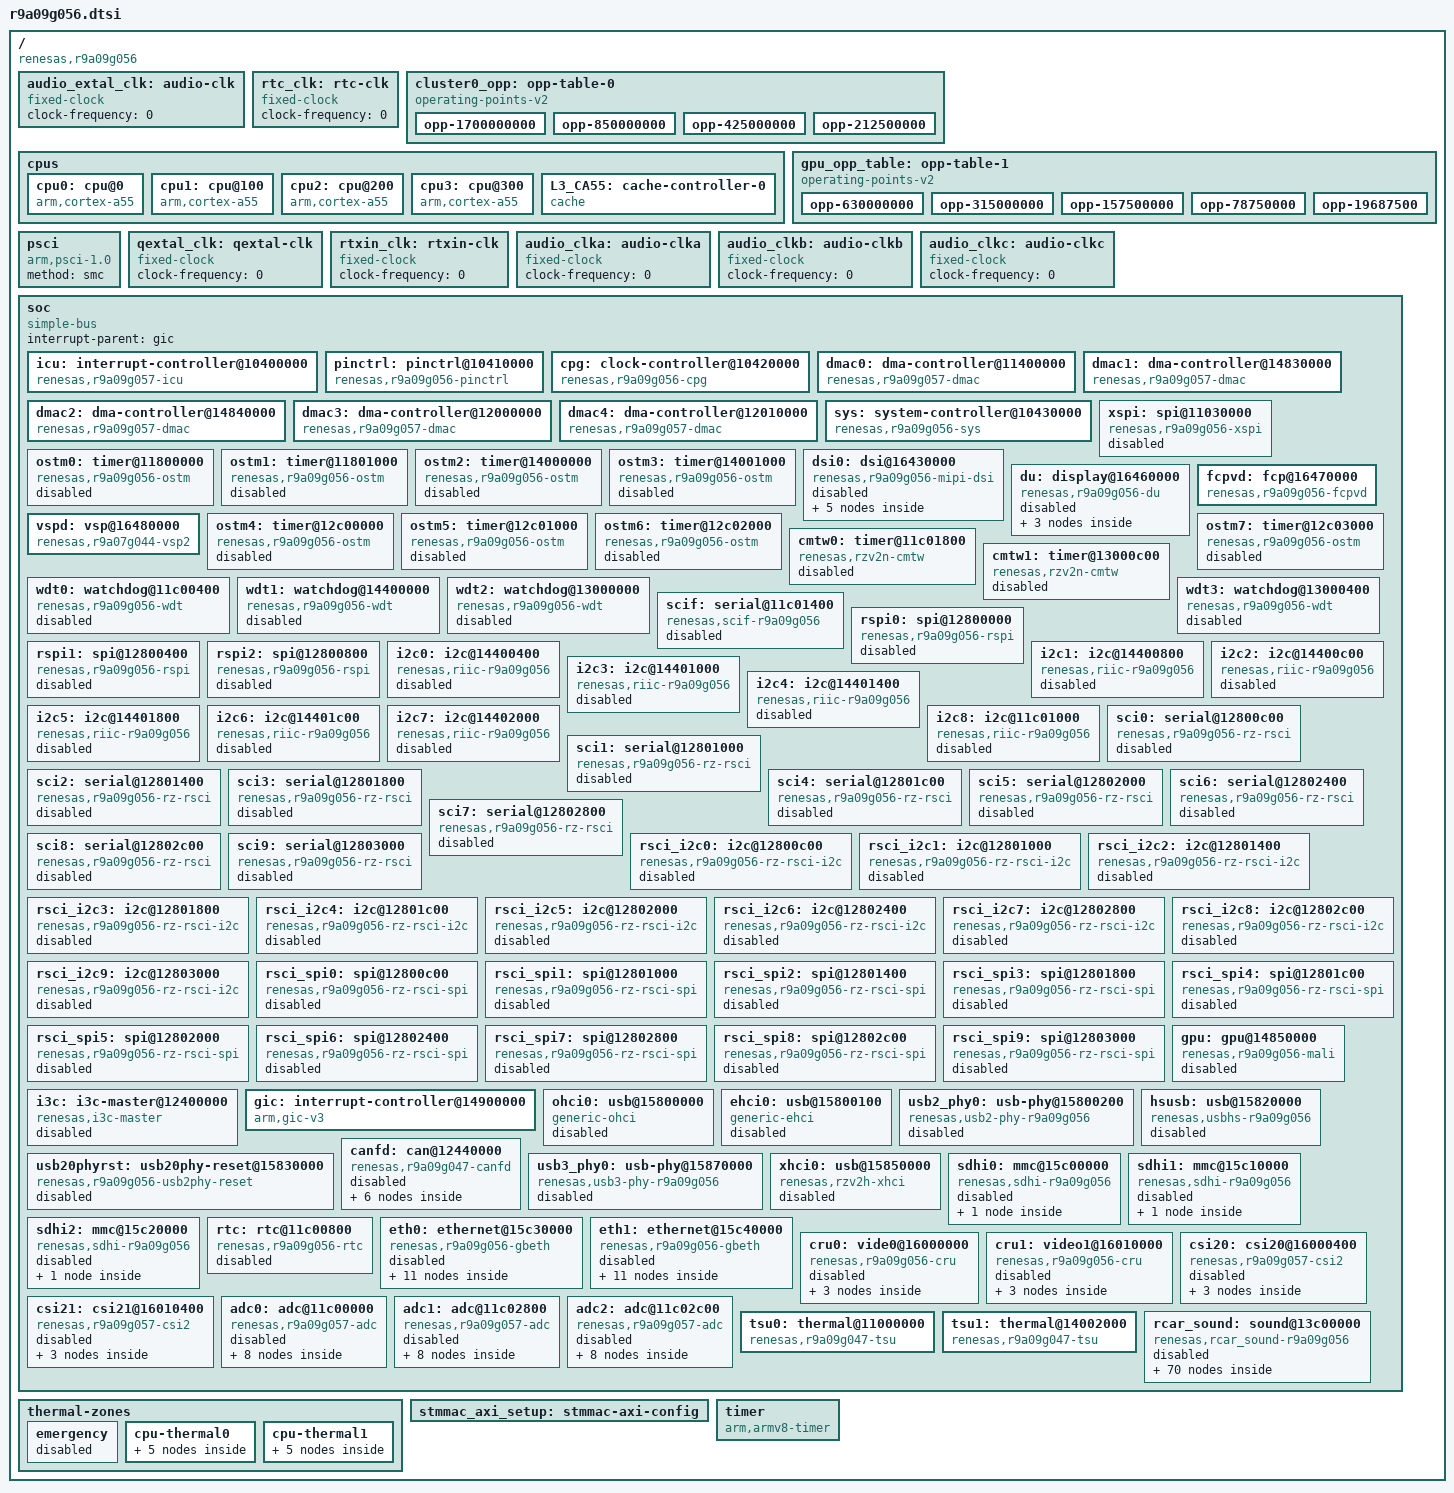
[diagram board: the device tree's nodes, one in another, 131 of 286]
// SPDX-License-Identifier: (GPL-2.0-only OR BSD-2-Clause)
/*
 * Device Tree Source for the RZ/V2N SoC
 *
 * Copyright (C) 2025 Renesas Electronics Corp.
 */

#include <dt-bindings/clock/renesas,r9a09g056-cpg.h>
#include <dt-bindings/interrupt-controller/arm-gic.h>
#include <dt-bindings/pinctrl/rzg2l-pinctrl.h>

/* RZV2N_Px = Offset address of PFC_P_mn  - 0x20 */
#define RZV2N_P0	0
#define RZV2N_P1	1
#define RZV2N_P2	2
#define RZV2N_P3	3
#define RZV2N_P4	4
#define RZV2N_P5	5
#define RZV2N_P6	6
#define RZV2N_P7	7
#define RZV2N_P8	8
#define RZV2N_P9	9
#define RZV2N_PA	10
#define RZV2N_PB	11

#define RZV2N_PORT_PINMUX(b, p, f)	RZG2L_PORT_PINMUX(RZV2N_P##b, p, f)
#define RZV2N_GPIO(port, pin)		RZG2L_GPIO(RZV2N_P##port, pin)

/ {
	compatible = "renesas,r9a09g056";
	#address-cells = <2>;
	#size-cells = <2>;

	audio_extal_clk: audio-clk {
		compatible = "fixed-clock";
		#clock-cells = <0>;
		/* This value must be overridden by the board */
		clock-frequency = <0>;
	};

	rtc_clk: rtc-clk {
		compatible = "fixed-clock";
		#clock-cells = <0>;
		/* This value must be overridden by the board */
		clock-frequency = <0>;
	};

	/*
	 * The default cluster table is based on the assumption that the PLLCA55 clock
	 * frequency is set to 1.7GHz. The PLLCA55 clock frequency can be set to
	 * 1.7/1.6/1.5/1.1 GHz based on the BOOTPLLCA_0/1 pins (and additionally can be
	 * clocked to 1.8GHz as well). The table below should be overridden in the board
	 * DTS based on the PLLCA55 clock frequency.
	 */
	cluster0_opp: opp-table-0 {
		compatible = "operating-points-v2";

		opp-1700000000 {
			opp-hz = /bits/ 64 <1700000000>;
			opp-microvolt = <900000>;
			clock-latency-ns = <300000>;
		};
		opp-850000000 {
			opp-hz = /bits/ 64 <850000000>;
			opp-microvolt = <800000>;
			clock-latency-ns = <300000>;
		};
		opp-425000000 {
			opp-hz = /bits/ 64 <425000000>;
			opp-microvolt = <800000>;
			clock-latency-ns = <300000>;
		};
		opp-212500000 {
			opp-hz = /bits/ 64 <212500000>;
			opp-microvolt = <800000>;
			clock-latency-ns = <300000>;
			opp-suspend;
		};
	};

	cpus {
		#address-cells = <1>;
		#size-cells = <0>;

		cpu0: cpu@0 {
			compatible = "arm,cortex-a55";
			reg = <0>;
			device_type = "cpu";
			next-level-cache = <&L3_CA55>;
			enable-method = "psci";
			clocks = <&cpg CPG_CORE R9A09G056_CA55_0_CORE_CLK0>;
			#cooling-cells = <2>;
			operating-points-v2 = <&cluster0_opp>;
		};

		cpu1: cpu@100 {
			compatible = "arm,cortex-a55";
			reg = <0x100>;
			device_type = "cpu";
			next-level-cache = <&L3_CA55>;
			enable-method = "psci";
			clocks = <&cpg CPG_CORE R9A09G056_CA55_0_CORE_CLK1>;
			#cooling-cells = <2>;
			operating-points-v2 = <&cluster0_opp>;
		};

		cpu2: cpu@200 {
			compatible = "arm,cortex-a55";
			reg = <0x200>;
			device_type = "cpu";
			next-level-cache = <&L3_CA55>;
			enable-method = "psci";
			clocks = <&cpg CPG_CORE R9A09G056_CA55_0_CORE_CLK2>;
			#cooling-cells = <2>;
			operating-points-v2 = <&cluster0_opp>;
		};

		cpu3: cpu@300 {
			compatible = "arm,cortex-a55";
			reg = <0x300>;
			device_type = "cpu";
			next-level-cache = <&L3_CA55>;
			enable-method = "psci";
			clocks = <&cpg CPG_CORE R9A09G056_CA55_0_CORE_CLK3>;
			#cooling-cells = <2>;
			operating-points-v2 = <&cluster0_opp>;
		};

		L3_CA55: cache-controller-0 {
			compatible = "cache";
			cache-unified;
			cache-size = <0x100000>;
			cache-level = <3>;
		};
	};

	gpu_opp_table: opp-table-1 {
		compatible = "operating-points-v2";

		opp-630000000 {
			opp-hz = /bits/ 64 <630000000>;
			opp-microvolt = <800000>;
		};

		opp-315000000 {
			opp-hz = /bits/ 64 <315000000>;
			opp-microvolt = <800000>;
		};

		opp-157500000 {
			opp-hz = /bits/ 64 <157500000>;
			opp-microvolt = <800000>;
		};

		opp-78750000 {
			opp-hz = /bits/ 64 <78750000>;
			opp-microvolt = <800000>;
		};

		opp-19687500 {
			opp-hz = /bits/ 64 <19687500>;
			opp-microvolt = <800000>;
		};
	};

	psci {
		compatible = "arm,psci-1.0", "arm,psci-0.2";
		method = "smc";
	};

	qextal_clk: qextal-clk {
		compatible = "fixed-clock";
		#clock-cells = <0>;
		/* This value must be overridden by the board */
		clock-frequency = <0>;
	};

	rtxin_clk: rtxin-clk {
		compatible = "fixed-clock";
		#clock-cells = <0>;
		/* This value must be overridden by the board */
		clock-frequency = <0>;
	};

	audio_clka: audio-clka {
		compatible = "fixed-clock";
		#clock-cells = <0>;
		/* This value must be overridden by the board */
		clock-frequency = <0>;
	};

	audio_clkb: audio-clkb {
		compatible = "fixed-clock";
		#clock-cells = <0>;
		/* This value must be overridden by the board */
		clock-frequency = <0>;
	};

	audio_clkc: audio-clkc {
		compatible = "fixed-clock";
		#clock-cells = <0>;
		/* This value must be overridden by the board */
		clock-frequency = <0>;
	};

	soc: soc {
		compatible = "simple-bus";
		interrupt-parent = <&gic>;
		#address-cells = <2>;
		#size-cells = <2>;
		ranges;

		icu: interrupt-controller@10400000 {
			compatible = "renesas,r9a09g057-icu";
			reg = <0 0x10400000 0 0x10000>;
			#interrupt-cells = <2>;
			#address-cells = <0>;
			interrupt-controller;
			interrupts = <GIC_SPI 0 IRQ_TYPE_LEVEL_HIGH>,
				     <GIC_SPI 1 IRQ_TYPE_LEVEL_HIGH>,
				     <GIC_SPI 2 IRQ_TYPE_LEVEL_HIGH>,
				     <GIC_SPI 3 IRQ_TYPE_LEVEL_HIGH>,
				     <GIC_SPI 4 IRQ_TYPE_LEVEL_HIGH>,
				     <GIC_SPI 5 IRQ_TYPE_LEVEL_HIGH>,
				     <GIC_SPI 6 IRQ_TYPE_LEVEL_HIGH>,
				     <GIC_SPI 7 IRQ_TYPE_LEVEL_HIGH>,
				     <GIC_SPI 8 IRQ_TYPE_LEVEL_HIGH>,
				     <GIC_SPI 9 IRQ_TYPE_LEVEL_HIGH>,
				     <GIC_SPI 10 IRQ_TYPE_LEVEL_HIGH>,
				     <GIC_SPI 11 IRQ_TYPE_LEVEL_HIGH>,
				     <GIC_SPI 12 IRQ_TYPE_LEVEL_HIGH>,
				     <GIC_SPI 13 IRQ_TYPE_LEVEL_HIGH>,
				     <GIC_SPI 14 IRQ_TYPE_LEVEL_HIGH>,
				     <GIC_SPI 15 IRQ_TYPE_LEVEL_HIGH>,
				     <GIC_SPI 16 IRQ_TYPE_LEVEL_HIGH>,
				     <GIC_SPI 419 IRQ_TYPE_LEVEL_HIGH>,
				     <GIC_SPI 420 IRQ_TYPE_LEVEL_HIGH>,
				     <GIC_SPI 421 IRQ_TYPE_LEVEL_HIGH>,
				     <GIC_SPI 422 IRQ_TYPE_LEVEL_HIGH>,
				     <GIC_SPI 423 IRQ_TYPE_LEVEL_HIGH>,
				     <GIC_SPI 424 IRQ_TYPE_LEVEL_HIGH>,
				     <GIC_SPI 425 IRQ_TYPE_LEVEL_HIGH>,
				     <GIC_SPI 426 IRQ_TYPE_LEVEL_HIGH>,
				     <GIC_SPI 427 IRQ_TYPE_LEVEL_HIGH>,
				     <GIC_SPI 428 IRQ_TYPE_LEVEL_HIGH>,
				     <GIC_SPI 429 IRQ_TYPE_LEVEL_HIGH>,
				     <GIC_SPI 430 IRQ_TYPE_LEVEL_HIGH>,
				     <GIC_SPI 431 IRQ_TYPE_LEVEL_HIGH>,
				     <GIC_SPI 432 IRQ_TYPE_LEVEL_HIGH>,
				     <GIC_SPI 433 IRQ_TYPE_LEVEL_HIGH>,
				     <GIC_SPI 434 IRQ_TYPE_LEVEL_HIGH>,
				     <GIC_SPI 435 IRQ_TYPE_LEVEL_HIGH>,
				     <GIC_SPI 436 IRQ_TYPE_LEVEL_HIGH>,
				     <GIC_SPI 437 IRQ_TYPE_LEVEL_HIGH>,
				     <GIC_SPI 438 IRQ_TYPE_LEVEL_HIGH>,
				     <GIC_SPI 439 IRQ_TYPE_LEVEL_HIGH>,
				     <GIC_SPI 440 IRQ_TYPE_LEVEL_HIGH>,
				     <GIC_SPI 441 IRQ_TYPE_LEVEL_HIGH>,
				     <GIC_SPI 442 IRQ_TYPE_LEVEL_HIGH>,
				     <GIC_SPI 443 IRQ_TYPE_LEVEL_HIGH>,
				     <GIC_SPI 444 IRQ_TYPE_LEVEL_HIGH>,
				     <GIC_SPI 445 IRQ_TYPE_LEVEL_HIGH>,
				     <GIC_SPI 446 IRQ_TYPE_LEVEL_HIGH>,
				     <GIC_SPI 447 IRQ_TYPE_LEVEL_HIGH>,
				     <GIC_SPI 448 IRQ_TYPE_LEVEL_HIGH>,
				     <GIC_SPI 449 IRQ_TYPE_LEVEL_HIGH>,
				     <GIC_SPI 450 IRQ_TYPE_LEVEL_HIGH>,
				     <GIC_SPI 262 IRQ_TYPE_EDGE_RISING>,
				     <GIC_SPI 263 IRQ_TYPE_EDGE_RISING>,
				     <GIC_SPI 264 IRQ_TYPE_EDGE_RISING>,
				     <GIC_SPI 265 IRQ_TYPE_EDGE_RISING>,
				     <GIC_SPI 266 IRQ_TYPE_LEVEL_HIGH>,
				     <GIC_SPI 451 IRQ_TYPE_LEVEL_HIGH>,
				     <GIC_SPI 452 IRQ_TYPE_LEVEL_HIGH>,
				     <GIC_SPI 453 IRQ_TYPE_LEVEL_HIGH>,
				     <GIC_SPI 454 IRQ_TYPE_LEVEL_HIGH>;
			interrupt-names = "nmi",
					  "port_irq0", "port_irq1", "port_irq2",
					  "port_irq3", "port_irq4", "port_irq5",
					  "port_irq6", "port_irq7", "port_irq8",
					  "port_irq9", "port_irq10", "port_irq11",
					  "port_irq12", "port_irq13", "port_irq14",
					  "port_irq15",
					  "tint0", "tint1", "tint2", "tint3",
					  "tint4", "tint5", "tint6", "tint7",
					  "tint8", "tint9", "tint10", "tint11",
					  "tint12", "tint13", "tint14", "tint15",
					  "tint16", "tint17", "tint18", "tint19",
					  "tint20", "tint21", "tint22", "tint23",
					  "tint24", "tint25", "tint26", "tint27",
					  "tint28", "tint29", "tint30", "tint31",
					  "int-ca55-0", "int-ca55-1",
					  "int-ca55-2", "int-ca55-3",
					  "icu-error-ca55",
					  "gpt-u0-gtciada", "gpt-u0-gtciadb",
					  "gpt-u1-gtciada", "gpt-u1-gtciadb";
			clocks = <&cpg CPG_MOD 0x5>;
			clock-names = "pclk";
			power-domains = <&cpg>;
			resets = <&cpg 0x36>;
		};

		pinctrl: pinctrl@10410000 {
			compatible = "renesas,r9a09g056-pinctrl";
			reg = <0 0x10410000 0 0x10000>;
			clocks = <&cpg CPG_CORE R9A09G056_IOTOP_0_SHCLK>;
			gpio-controller;
			#gpio-cells = <2>;
			gpio-ranges = <&pinctrl 0 0 96>;
			interrupt-parent = <&icu>;
			power-domains = <&cpg>;
			resets = <&cpg 0xa5>, <&cpg 0xa6>;
		};

		cpg: clock-controller@10420000 {
			compatible = "renesas,r9a09g056-cpg";
			reg = <0 0x10420000 0 0x10000>;
			clocks = <&audio_extal_clk>, <&audio_clka>,
				 <&audio_clkb>, <&audio_clkc>,
				 <&rtxin_clk>, <&qextal_clk>;
			clock-names = "audio_extal", "audio_clka",
				      "audio_clkb", "audio_clkc",
				      "rtxin", "qextal";
			#clock-cells = <2>;
			#reset-cells = <1>;
			#power-domain-cells = <0>;
		};

		dmac0: dma-controller@11400000 {
			compatible = "renesas,r9a09g057-dmac";
			reg = <0 0x11400000 0 0x10000>;
			interrupts = <GIC_SPI 499 IRQ_TYPE_EDGE_RISING>,
				     <GIC_SPI 89 IRQ_TYPE_EDGE_RISING>,
				     <GIC_SPI 90 IRQ_TYPE_EDGE_RISING>,
				     <GIC_SPI 91 IRQ_TYPE_EDGE_RISING>,
				     <GIC_SPI 92 IRQ_TYPE_EDGE_RISING>,
				     <GIC_SPI 93 IRQ_TYPE_EDGE_RISING>,
				     <GIC_SPI 94 IRQ_TYPE_EDGE_RISING>,
				     <GIC_SPI 95 IRQ_TYPE_EDGE_RISING>,
				     <GIC_SPI 96 IRQ_TYPE_EDGE_RISING>,
				     <GIC_SPI 97 IRQ_TYPE_EDGE_RISING>,
				     <GIC_SPI 98 IRQ_TYPE_EDGE_RISING>,
				     <GIC_SPI 99 IRQ_TYPE_EDGE_RISING>,
				     <GIC_SPI 100 IRQ_TYPE_EDGE_RISING>,
				     <GIC_SPI 101 IRQ_TYPE_EDGE_RISING>,
				     <GIC_SPI 102 IRQ_TYPE_EDGE_RISING>,
				     <GIC_SPI 103 IRQ_TYPE_EDGE_RISING>,
				     <GIC_SPI 104 IRQ_TYPE_EDGE_RISING>;
			interrupt-names = "error",
					  "ch0", "ch1", "ch2", "ch3",
					  "ch4", "ch5", "ch6", "ch7",
					  "ch8", "ch9", "ch10", "ch11",
					  "ch12", "ch13", "ch14", "ch15";
			clocks = <&cpg CPG_MOD 0x0>;
			power-domains = <&cpg>;
			resets = <&cpg 0x31>;
			#dma-cells = <1>;
			dma-channels = <16>;
			renesas,icu = <&icu 4>;
		};

		dmac1: dma-controller@14830000 {
			compatible = "renesas,r9a09g057-dmac";
			reg = <0 0x14830000 0 0x10000>;
			interrupts = <GIC_SPI 495 IRQ_TYPE_EDGE_RISING>,
				     <GIC_SPI 25 IRQ_TYPE_EDGE_RISING>,
				     <GIC_SPI 26 IRQ_TYPE_EDGE_RISING>,
				     <GIC_SPI 27 IRQ_TYPE_EDGE_RISING>,
				     <GIC_SPI 28 IRQ_TYPE_EDGE_RISING>,
				     <GIC_SPI 29 IRQ_TYPE_EDGE_RISING>,
				     <GIC_SPI 30 IRQ_TYPE_EDGE_RISING>,
				     <GIC_SPI 31 IRQ_TYPE_EDGE_RISING>,
				     <GIC_SPI 32 IRQ_TYPE_EDGE_RISING>,
				     <GIC_SPI 33 IRQ_TYPE_EDGE_RISING>,
				     <GIC_SPI 34 IRQ_TYPE_EDGE_RISING>,
				     <GIC_SPI 35 IRQ_TYPE_EDGE_RISING>,
				     <GIC_SPI 36 IRQ_TYPE_EDGE_RISING>,
				     <GIC_SPI 37 IRQ_TYPE_EDGE_RISING>,
				     <GIC_SPI 38 IRQ_TYPE_EDGE_RISING>,
				     <GIC_SPI 39 IRQ_TYPE_EDGE_RISING>,
				     <GIC_SPI 40 IRQ_TYPE_EDGE_RISING>;
			interrupt-names = "error",
					  "ch0", "ch1", "ch2", "ch3",
					  "ch4", "ch5", "ch6", "ch7",
					  "ch8", "ch9", "ch10", "ch11",
					  "ch12", "ch13", "ch14", "ch15";
			clocks = <&cpg CPG_MOD 0x1>;
			power-domains = <&cpg>;
			resets = <&cpg 0x32>;
			#dma-cells = <1>;
			dma-channels = <16>;
			renesas,icu = <&icu 0>;
		};

		dmac2: dma-controller@14840000 {
			compatible = "renesas,r9a09g057-dmac";
			reg = <0 0x14840000 0 0x10000>;
			interrupts = <GIC_SPI 496 IRQ_TYPE_EDGE_RISING>,
				     <GIC_SPI 41 IRQ_TYPE_EDGE_RISING>,
				     <GIC_SPI 42 IRQ_TYPE_EDGE_RISING>,
				     <GIC_SPI 43 IRQ_TYPE_EDGE_RISING>,
				     <GIC_SPI 44 IRQ_TYPE_EDGE_RISING>,
				     <GIC_SPI 45 IRQ_TYPE_EDGE_RISING>,
				     <GIC_SPI 46 IRQ_TYPE_EDGE_RISING>,
				     <GIC_SPI 47 IRQ_TYPE_EDGE_RISING>,
				     <GIC_SPI 48 IRQ_TYPE_EDGE_RISING>,
				     <GIC_SPI 49 IRQ_TYPE_EDGE_RISING>,
				     <GIC_SPI 50 IRQ_TYPE_EDGE_RISING>,
				     <GIC_SPI 51 IRQ_TYPE_EDGE_RISING>,
				     <GIC_SPI 52 IRQ_TYPE_EDGE_RISING>,
				     <GIC_SPI 53 IRQ_TYPE_EDGE_RISING>,
				     <GIC_SPI 54 IRQ_TYPE_EDGE_RISING>,
				     <GIC_SPI 55 IRQ_TYPE_EDGE_RISING>,
				     <GIC_SPI 56 IRQ_TYPE_EDGE_RISING>;
			interrupt-names = "error",
					  "ch0", "ch1", "ch2", "ch3",
					  "ch4", "ch5", "ch6", "ch7",
					  "ch8", "ch9", "ch10", "ch11",
					  "ch12", "ch13", "ch14", "ch15";
			clocks = <&cpg CPG_MOD 0x2>;
			power-domains = <&cpg>;
			resets = <&cpg 0x33>;
			#dma-cells = <1>;
			dma-channels = <16>;
			renesas,icu = <&icu 1>;
		};

		dmac3: dma-controller@12000000 {
			compatible = "renesas,r9a09g057-dmac";
			reg = <0 0x12000000 0 0x10000>;
			interrupts = <GIC_SPI 497 IRQ_TYPE_EDGE_RISING>,
				     <GIC_SPI 57 IRQ_TYPE_EDGE_RISING>,
				     <GIC_SPI 58 IRQ_TYPE_EDGE_RISING>,
				     <GIC_SPI 59 IRQ_TYPE_EDGE_RISING>,
				     <GIC_SPI 60 IRQ_TYPE_EDGE_RISING>,
				     <GIC_SPI 61 IRQ_TYPE_EDGE_RISING>,
				     <GIC_SPI 62 IRQ_TYPE_EDGE_RISING>,
				     <GIC_SPI 63 IRQ_TYPE_EDGE_RISING>,
				     <GIC_SPI 64 IRQ_TYPE_EDGE_RISING>,
				     <GIC_SPI 65 IRQ_TYPE_EDGE_RISING>,
				     <GIC_SPI 66 IRQ_TYPE_EDGE_RISING>,
				     <GIC_SPI 67 IRQ_TYPE_EDGE_RISING>,
				     <GIC_SPI 68 IRQ_TYPE_EDGE_RISING>,
				     <GIC_SPI 69 IRQ_TYPE_EDGE_RISING>,
				     <GIC_SPI 70 IRQ_TYPE_EDGE_RISING>,
				     <GIC_SPI 71 IRQ_TYPE_EDGE_RISING>,
				     <GIC_SPI 72 IRQ_TYPE_EDGE_RISING>;
			interrupt-names = "error",
					  "ch0", "ch1", "ch2", "ch3",
					  "ch4", "ch5", "ch6", "ch7",
					  "ch8", "ch9", "ch10", "ch11",
					  "ch12", "ch13", "ch14", "ch15";
			clocks = <&cpg CPG_MOD 0x3>;
			power-domains = <&cpg>;
			resets = <&cpg 0x34>;
			#dma-cells = <1>;
			dma-channels = <16>;
			renesas,icu = <&icu 2>;
		};

		dmac4: dma-controller@12010000 {
			compatible = "renesas,r9a09g057-dmac";
			reg = <0 0x12010000 0 0x10000>;
			interrupts = <GIC_SPI 498 IRQ_TYPE_EDGE_RISING>,
				     <GIC_SPI 73 IRQ_TYPE_EDGE_RISING>,
				     <GIC_SPI 74 IRQ_TYPE_EDGE_RISING>,
				     <GIC_SPI 75 IRQ_TYPE_EDGE_RISING>,
				     <GIC_SPI 76 IRQ_TYPE_EDGE_RISING>,
				     <GIC_SPI 77 IRQ_TYPE_EDGE_RISING>,
				     <GIC_SPI 78 IRQ_TYPE_EDGE_RISING>,
				     <GIC_SPI 79 IRQ_TYPE_EDGE_RISING>,
				     <GIC_SPI 80 IRQ_TYPE_EDGE_RISING>,
				     <GIC_SPI 81 IRQ_TYPE_EDGE_RISING>,
				     <GIC_SPI 82 IRQ_TYPE_EDGE_RISING>,
				     <GIC_SPI 83 IRQ_TYPE_EDGE_RISING>,
				     <GIC_SPI 84 IRQ_TYPE_EDGE_RISING>,
				     <GIC_SPI 85 IRQ_TYPE_EDGE_RISING>,
				     <GIC_SPI 86 IRQ_TYPE_EDGE_RISING>,
				     <GIC_SPI 87 IRQ_TYPE_EDGE_RISING>,
				     <GIC_SPI 88 IRQ_TYPE_EDGE_RISING>;
			interrupt-names = "error",
					  "ch0", "ch1", "ch2", "ch3",
					  "ch4", "ch5", "ch6", "ch7",
					  "ch8", "ch9", "ch10", "ch11",
					  "ch12", "ch13", "ch14", "ch15";
			clocks = <&cpg CPG_MOD 0x4>;
			power-domains = <&cpg>;
			resets = <&cpg 0x35>;
			#dma-cells = <1>;
			dma-channels = <16>;
			renesas,icu = <&icu 3>;
		};

		sys: system-controller@10430000 {
			compatible = "renesas,r9a09g056-sys", "syscon";
			reg = <0 0x10430000 0 0x10000>;
			clocks = <&cpg CPG_CORE R9A09G056_SYS_0_PCLK>;
			resets = <&cpg 0x30>;
		};

		xspi: spi@11030000 {
			compatible = "renesas,r9a09g056-xspi", "renesas,r9a09g047-xspi";
			reg = <0 0x11030000 0 0x10000>,
			      <0 0x20000000 0 0x10000000>;
			reg-names = "regs", "dirmap";
			interrupts = <GIC_SPI 228 IRQ_TYPE_EDGE_RISING>,
				     <GIC_SPI 229 IRQ_TYPE_EDGE_RISING>;
			interrupt-names = "pulse", "err_pulse";
			clocks = <&cpg CPG_MOD 0x9f>,
				 <&cpg CPG_MOD 0xa0>,
				 <&cpg CPG_CORE R9A09G056_SPI_CLK_SPI>,
				 <&cpg CPG_MOD 0xa1>;
			clock-names = "ahb", "axi", "spi", "spix2";
			resets = <&cpg 0xa3>, <&cpg 0xa4>;
			reset-names = "hresetn", "aresetn";
			power-domains = <&cpg>;
			#address-cells = <1>;
			#size-cells = <0>;
			status = "disabled";
		};

		ostm0: timer@11800000 {
			compatible = "renesas,r9a09g056-ostm", "renesas,ostm";
			reg = <0x0 0x11800000 0x0 0x1000>;
			interrupts = <GIC_SPI 17 IRQ_TYPE_EDGE_RISING>;
			clocks = <&cpg CPG_MOD 0x43>;
			resets = <&cpg 0x6d>;
			power-domains = <&cpg>;
			status = "disabled";
		};

		ostm1: timer@11801000 {
			compatible = "renesas,r9a09g056-ostm", "renesas,ostm";
			reg = <0x0 0x11801000 0x0 0x1000>;
			interrupts = <GIC_SPI 18 IRQ_TYPE_EDGE_RISING>;
			clocks = <&cpg CPG_MOD 0x44>;
			resets = <&cpg 0x6e>;
			power-domains = <&cpg>;
			status = "disabled";
		};

		ostm2: timer@14000000 {
			compatible = "renesas,r9a09g056-ostm", "renesas,ostm";
			reg = <0x0 0x14000000 0x0 0x1000>;
			interrupts = <GIC_SPI 19 IRQ_TYPE_EDGE_RISING>;
			clocks = <&cpg CPG_MOD 0x45>;
			resets = <&cpg 0x6f>;
			power-domains = <&cpg>;
			status = "disabled";
		};

		ostm3: timer@14001000 {
			compatible = "renesas,r9a09g056-ostm", "renesas,ostm";
			reg = <0x0 0x14001000 0x0 0x1000>;
			interrupts = <GIC_SPI 20 IRQ_TYPE_EDGE_RISING>;
			clocks = <&cpg CPG_MOD 0x46>;
			resets = <&cpg 0x70>;
			power-domains = <&cpg>;
			status = "disabled";
		};

		dsi0: dsi@16430000 {
			compatible = "renesas,r9a09g056-mipi-dsi",
				     "renesas,rzv2n-mipi-dsi";
			reg = <0 0x16430000 0 0x20000>;
			clocks = <&cpg CPG_MOD 0xe8>,
				 <&cpg CPG_MOD 0xe9>,
				 <&cpg CPG_MOD 0xea>,
				 <&cpg CPG_MOD 0xeb>,
				 <&cpg CPG_MOD 0xec>;
			clock-names = "pclk", "aclk",
				      "vclk0", "lpclk", "pllclk";
			resets = <&cpg 0xd7>,
				 <&cpg 0xd8>;
			reset-names = "prst", "arst";
			power-domains = <&cpg>;
			status = "disabled";

			ports {
				#address-cells = <1>;
				#size-cells = <0>;

				port@0 {
					reg = <0>;
					dsi0_in: endpoint {
						remote-endpoint = <&du_out_dsi0>;
					};
				};

				port@1 {
					reg = <1>;
					dsi0_out: endpoint {
					};
				};
			};
		};

		du: display@16460000 {
			compatible = "renesas,r9a09g056-du";
			reg = <0 0x16460000 0 0x10000>;
			interrupts = <GIC_SPI 882 IRQ_TYPE_LEVEL_HIGH>;
			clocks = <&cpg CPG_MOD 0xed>,
				 <&cpg CPG_MOD 0xee>,
				 <&cpg CPG_MOD 0xef>;
			clock-names = "aclk0", "pclk0", "vclk0";
			power-domains = <&cpg>;
			resets = <&cpg 0xdc>;
			renesas,vsps = <&vspd 0>;
			status = "disabled";

			ports {
				#address-cells = <1>;
				#size-cells = <0>;

				port@0 {
					reg = <0>;
					du_out_dsi0: endpoint {
						remote-endpoint = <&dsi0_in>;
					};
				};
			};
		};

		fcpvd: fcp@16470000 {
			compatible = "renesas,r9a09g056-fcpvd",
				     "renesas,fcpv";
			reg = <0 0x10880000 0 0x10000>;
			clocks = <&cpg CPG_MOD 0xed>,
				 <&cpg CPG_MOD 0xee>,
				 <&cpg CPG_MOD 0xef>;
			clock-names = "aclk", "pclk", "vclk";
			resets = <&cpg 0xdc>;
			power-domains = <&cpg>;
		};

		vspd: vsp@16480000 {
			compatible = "renesas,r9a07g044-vsp2";
			reg = <0 0x16480000 0 0x10000>;
			interrupts = <GIC_SPI 881 IRQ_TYPE_LEVEL_HIGH>;
			clocks = <&cpg CPG_MOD 0xed>,
				 <&cpg CPG_MOD 0xee>,
				 <&cpg CPG_MOD 0xef>;
			clock-names = "aclk", "pclk", "vclk";
			resets = <&cpg 0xdc>;
			power-domains = <&cpg>;
			renesas,fcp = <&fcpvd>;
		};

		ostm4: timer@12c00000 {
			compatible = "renesas,r9a09g056-ostm", "renesas,ostm";
			reg = <0x0 0x12c00000 0x0 0x1000>;
			interrupts = <GIC_SPI 21 IRQ_TYPE_EDGE_RISING>;
			clocks = <&cpg CPG_MOD 0x47>;
			resets = <&cpg 0x71>;
			power-domains = <&cpg>;
			status = "disabled";
		};

		ostm5: timer@12c01000 {
			compatible = "renesas,r9a09g056-ostm", "renesas,ostm";
			reg = <0x0 0x12c01000 0x0 0x1000>;
			interrupts = <GIC_SPI 22 IRQ_TYPE_EDGE_RISING>;
			clocks = <&cpg CPG_MOD 0x48>;
			resets = <&cpg 0x72>;
			power-domains = <&cpg>;
			status = "disabled";
		};

		ostm6: timer@12c02000 {
			compatible = "renesas,r9a09g056-ostm", "renesas,ostm";
			reg = <0x0 0x12c02000 0x0 0x1000>;
			interrupts = <GIC_SPI 23 IRQ_TYPE_EDGE_RISING>;
			clocks = <&cpg CPG_MOD 0x49>;
			resets = <&cpg 0x73>;
			power-domains = <&cpg>;
			status = "disabled";
		};

		ostm7: timer@12c03000 {
			compatible = "renesas,r9a09g056-ostm", "renesas,ostm";
			reg = <0x0 0x12c03000 0x0 0x1000>;
			interrupts = <GIC_SPI 24 IRQ_TYPE_EDGE_RISING>;
			clocks = <&cpg CPG_MOD 0x4a>;
			resets = <&cpg 0x74>;
			power-domains = <&cpg>;
			status = "disabled";
		};

		cmtw0: timer@11c01800 {
			compatible = "renesas,rzv2n-cmtw";
			reg = <0 0x11c01800 0 0x1000>;
			interrupts = <GIC_SPI 455 IRQ_TYPE_EDGE_RISING>,
				     <GIC_SPI 456 IRQ_TYPE_EDGE_RISING>,
				     <GIC_SPI 457 IRQ_TYPE_EDGE_RISING>,
				     <GIC_SPI 458 IRQ_TYPE_EDGE_RISING>;
			clocks = <&cpg CPG_MOD 0x3b>, <&cpg CPG_MOD 0x3c>,
				 <&cpg CPG_MOD 0x3d>, <&cpg CPG_MOD 0x3e>;
			clock-names = "fck0", "fck1", "fck2", "fck3";
			resets = <&cpg 0x65>, <&cpg 0x66>,
				 <&cpg 0x67>, <&cpg 0x68>;
			power-domains = <&cpg>;
			status = "disabled";
		};

		cmtw1: timer@13000c00 {
			compatible = "renesas,rzv2n-cmtw";
			reg = <0 0x13000c00 0 0x1000>;
			interrupts = <GIC_SPI 459 IRQ_TYPE_EDGE_RISING>,
				     <GIC_SPI 460 IRQ_TYPE_EDGE_RISING>,
				     <GIC_SPI 461 IRQ_TYPE_EDGE_RISING>,
				     <GIC_SPI 462 IRQ_TYPE_EDGE_RISING>;
			clocks = <&cpg CPG_MOD 0x3f>, <&cpg CPG_MOD 0x40>,
				 <&cpg CPG_MOD 0x41>, <&cpg CPG_MOD 0x42>;
			clock-names = "fck0", "fck1", "fck2", "fck3";
			resets = <&cpg 0x69>, <&cpg 0x6a>,
				 <&cpg 0x6b>, <&cpg 0x6c>;
			power-domains = <&cpg>;
			status = "disabled";
		};

		wdt0: watchdog@11c00400 {
			compatible = "renesas,r9a09g056-wdt", "renesas,r9a09g057-wdt";
			reg = <0 0x11c00400 0 0x400>;
			clocks = <&cpg CPG_MOD 0x4b>, <&cpg CPG_MOD 0x4c>;
			clock-names = "pclk", "oscclk";
			resets = <&cpg 0x75>;
			power-domains = <&cpg>;
			status = "disabled";
		};

		wdt1: watchdog@14400000 {
			compatible = "renesas,r9a09g056-wdt", "renesas,r9a09g057-wdt";
			reg = <0 0x14400000 0 0x400>;
			clocks = <&cpg CPG_MOD 0x4d>, <&cpg CPG_MOD 0x4e>;
			clock-names = "pclk", "oscclk";
			resets = <&cpg 0x76>;
			power-domains = <&cpg>;
			status = "disabled";
		};

		wdt2: watchdog@13000000 {
			compatible = "renesas,r9a09g056-wdt", "renesas,r9a09g057-wdt";
			reg = <0 0x13000000 0 0x400>;
			clocks = <&cpg CPG_MOD 0x4f>, <&cpg CPG_MOD 0x50>;
			clock-names = "pclk", "oscclk";
			resets = <&cpg 0x77>;
			power-domains = <&cpg>;
			status = "disabled";
		};

		wdt3: watchdog@13000400 {
			compatible = "renesas,r9a09g056-wdt", "renesas,r9a09g057-wdt";
			reg = <0 0x13000400 0 0x400>;
			clocks = <&cpg CPG_MOD 0x51>, <&cpg CPG_MOD 0x52>;
			clock-names = "pclk", "oscclk";
			resets = <&cpg 0x78>;
			power-domains = <&cpg>;
			status = "disabled";
		};

		scif: serial@11c01400 {
			compatible = "renesas,scif-r9a09g056",
				     "renesas,scif-r9a09g057";
			reg = <0 0x11c01400 0 0x400>;
			interrupts = <GIC_SPI 529 IRQ_TYPE_LEVEL_HIGH>,
				     <GIC_SPI 532 IRQ_TYPE_LEVEL_HIGH>,
				     <GIC_SPI 533 IRQ_TYPE_LEVEL_HIGH>,
				     <GIC_SPI 530 IRQ_TYPE_LEVEL_HIGH>,
				     <GIC_SPI 534 IRQ_TYPE_LEVEL_HIGH>,
				     <GIC_SPI 531 IRQ_TYPE_LEVEL_HIGH>,
				     <GIC_SPI 535 IRQ_TYPE_LEVEL_HIGH>,
				     <GIC_SPI 536 IRQ_TYPE_EDGE_RISING>,
				     <GIC_SPI 537 IRQ_TYPE_EDGE_RISING>;
			interrupt-names = "eri", "rxi", "txi", "bri", "dri",
					  "tei", "tei-dri", "rxi-edge", "txi-edge";
			clocks = <&cpg CPG_MOD 0x8f>;
			clock-names = "fck";
			power-domains = <&cpg>;
			resets = <&cpg 0x95>;
			status = "disabled";
		};

		rspi0: spi@12800000 {
			compatible = "renesas,r9a09g056-rspi",
				     "renesas,r9a09g057-rspi";
			reg = <0x0 0x12800000 0x0 0x400>;
			interrupts = <GIC_SPI 105 IRQ_TYPE_LEVEL_HIGH>,
				     <GIC_SPI 106 IRQ_TYPE_LEVEL_HIGH>,
				     <GIC_SPI 107 IRQ_TYPE_EDGE_RISING>,
				     <GIC_SPI 500 IRQ_TYPE_EDGE_RISING>,
				     <GIC_SPI 501 IRQ_TYPE_EDGE_RISING>;
			interrupt-names = "idle", "error", "end", "rx", "tx";
			clocks = <&cpg CPG_MOD 0x54>,
				 <&cpg CPG_MOD 0x55>,
				 <&cpg CPG_MOD 0x56>;
			clock-names = "pclk", "pclk_sfr", "tclk";
			resets = <&cpg 0x7b>, <&cpg 0x7c>;
			reset-names = "presetn", "tresetn";
			power-domains = <&cpg>;
			#address-cells = <1>;
			#size-cells = <0>;
			status = "disabled";
		};

		rspi1: spi@12800400 {
			compatible = "renesas,r9a09g056-rspi",
				     "renesas,r9a09g057-rspi";
			reg = <0x0 0x12800400 0x0 0x400>;
			interrupts = <GIC_SPI 108 IRQ_TYPE_LEVEL_HIGH>,
				     <GIC_SPI 109 IRQ_TYPE_LEVEL_HIGH>,
				     <GIC_SPI 110 IRQ_TYPE_EDGE_RISING>,
				     <GIC_SPI 502 IRQ_TYPE_EDGE_RISING>,
				     <GIC_SPI 503 IRQ_TYPE_EDGE_RISING>;
			interrupt-names = "idle", "error", "end", "rx", "tx";
			clocks = <&cpg CPG_MOD 0x57>,
				 <&cpg CPG_MOD 0x58>,
				 <&cpg CPG_MOD 0x59>;
			clock-names = "pclk", "pclk_sfr", "tclk";
			resets = <&cpg 0x7d>, <&cpg 0x7e>;
			reset-names = "presetn", "tresetn";
			power-domains = <&cpg>;
			#address-cells = <1>;
			#size-cells = <0>;
			status = "disabled";
		};

		rspi2: spi@12800800 {
			compatible = "renesas,r9a09g056-rspi",
				     "renesas,r9a09g057-rspi";
			reg = <0x0 0x12800800 0x0 0x400>;
			interrupts = <GIC_SPI 111 IRQ_TYPE_LEVEL_HIGH>,
				     <GIC_SPI 112 IRQ_TYPE_LEVEL_HIGH>,
				     <GIC_SPI 113 IRQ_TYPE_EDGE_RISING>,
				     <GIC_SPI 504 IRQ_TYPE_EDGE_RISING>,
				     <GIC_SPI 505 IRQ_TYPE_EDGE_RISING>;
			interrupt-names = "idle", "error", "end", "rx", "tx";
			clocks = <&cpg CPG_MOD 0x5a>,
				 <&cpg CPG_MOD 0x5b>,
				 <&cpg CPG_MOD 0x5c>;
			clock-names = "pclk", "pclk_sfr", "tclk";
			resets = <&cpg 0x7f>, <&cpg 0x80>;
			reset-names = "presetn", "tresetn";
			dmas = <&dmac1 0x4491>, <&dmac1 0x4490>;
			dma-names = "tx", "rx";
			power-domains = <&cpg>;
			#address-cells = <1>;
			#size-cells = <0>;
			status = "disabled";
		};

		i2c0: i2c@14400400 {
			compatible = "renesas,riic-r9a09g056", "renesas,riic-r9a09g057";
			reg = <0 0x14400400 0 0x400>;
			interrupts = <GIC_SPI 174 IRQ_TYPE_LEVEL_HIGH>,
				     <GIC_SPI 507 IRQ_TYPE_EDGE_RISING>,
				     <GIC_SPI 506 IRQ_TYPE_EDGE_RISING>,
				     <GIC_SPI 176 IRQ_TYPE_LEVEL_HIGH>,
				     <GIC_SPI 177 IRQ_TYPE_LEVEL_HIGH>,
				     <GIC_SPI 175 IRQ_TYPE_LEVEL_HIGH>,
				     <GIC_SPI 178 IRQ_TYPE_LEVEL_HIGH>,
				     <GIC_SPI 179 IRQ_TYPE_LEVEL_HIGH>;
			interrupt-names = "tei", "ri", "ti", "spi", "sti",
					  "naki", "ali", "tmoi";
			clocks = <&cpg CPG_MOD 0x94>;
			resets = <&cpg 0x98>;
			power-domains = <&cpg>;
			#address-cells = <1>;
			#size-cells = <0>;
			status = "disabled";
		};

		i2c1: i2c@14400800 {
			compatible = "renesas,riic-r9a09g056", "renesas,riic-r9a09g057";
			reg = <0 0x14400800 0 0x400>;
			interrupts = <GIC_SPI 180 IRQ_TYPE_LEVEL_HIGH>,
				     <GIC_SPI 509 IRQ_TYPE_EDGE_RISING>,
				     <GIC_SPI 508 IRQ_TYPE_EDGE_RISING>,
				     <GIC_SPI 182 IRQ_TYPE_LEVEL_HIGH>,
				     <GIC_SPI 183 IRQ_TYPE_LEVEL_HIGH>,
				     <GIC_SPI 181 IRQ_TYPE_LEVEL_HIGH>,
				     <GIC_SPI 184 IRQ_TYPE_LEVEL_HIGH>,
				     <GIC_SPI 185 IRQ_TYPE_LEVEL_HIGH>;
			interrupt-names = "tei", "ri", "ti", "spi", "sti",
					  "naki", "ali", "tmoi";
			clocks = <&cpg CPG_MOD 0x95>;
			resets = <&cpg 0x99>;
			power-domains = <&cpg>;
			#address-cells = <1>;
			#size-cells = <0>;
			status = "disabled";
		};

		i2c2: i2c@14400c00 {
			compatible = "renesas,riic-r9a09g056", "renesas,riic-r9a09g057";
			reg = <0 0x14400c00 0 0x400>;
			interrupts = <GIC_SPI 186 IRQ_TYPE_LEVEL_HIGH>,
				     <GIC_SPI 511 IRQ_TYPE_EDGE_RISING>,
				     <GIC_SPI 510 IRQ_TYPE_EDGE_RISING>,
				     <GIC_SPI 188 IRQ_TYPE_LEVEL_HIGH>,
				     <GIC_SPI 189 IRQ_TYPE_LEVEL_HIGH>,
				     <GIC_SPI 187 IRQ_TYPE_LEVEL_HIGH>,
				     <GIC_SPI 190 IRQ_TYPE_LEVEL_HIGH>,
				     <GIC_SPI 191 IRQ_TYPE_LEVEL_HIGH>;
			interrupt-names = "tei", "ri", "ti", "spi", "sti",
					  "naki", "ali", "tmoi";
			clocks = <&cpg CPG_MOD 0x96>;
			resets = <&cpg 0x9a>;
			power-domains = <&cpg>;
			#address-cells = <1>;
			#size-cells = <0>;
			status = "disabled";
		};

		i2c3: i2c@14401000 {
			compatible = "renesas,riic-r9a09g056", "renesas,riic-r9a09g057";
			reg = <0 0x14401000 0 0x400>;
			interrupts = <GIC_SPI 192 IRQ_TYPE_LEVEL_HIGH>,
				     <GIC_SPI 513 IRQ_TYPE_EDGE_RISING>,
				     <GIC_SPI 512 IRQ_TYPE_EDGE_RISING>,
				     <GIC_SPI 194 IRQ_TYPE_LEVEL_HIGH>,
				     <GIC_SPI 195 IRQ_TYPE_LEVEL_HIGH>,
				     <GIC_SPI 193 IRQ_TYPE_LEVEL_HIGH>,
				     <GIC_SPI 196 IRQ_TYPE_LEVEL_HIGH>,
				     <GIC_SPI 197 IRQ_TYPE_LEVEL_HIGH>;
			interrupt-names = "tei", "ri", "ti", "spi", "sti",
					  "naki", "ali", "tmoi";
			clocks = <&cpg CPG_MOD 0x97>;
			resets = <&cpg 0x9b>;
			power-domains = <&cpg>;
			#address-cells = <1>;
			#size-cells = <0>;
			status = "disabled";
		};

		i2c4: i2c@14401400 {
			compatible = "renesas,riic-r9a09g056", "renesas,riic-r9a09g057";
			reg = <0 0x14401400 0 0x400>;
			interrupts = <GIC_SPI 198 IRQ_TYPE_LEVEL_HIGH>,
				     <GIC_SPI 515 IRQ_TYPE_EDGE_RISING>,
				     <GIC_SPI 514 IRQ_TYPE_EDGE_RISING>,
				     <GIC_SPI 200 IRQ_TYPE_LEVEL_HIGH>,
				     <GIC_SPI 201 IRQ_TYPE_LEVEL_HIGH>,
				     <GIC_SPI 199 IRQ_TYPE_LEVEL_HIGH>,
				     <GIC_SPI 202 IRQ_TYPE_LEVEL_HIGH>,
				     <GIC_SPI 203 IRQ_TYPE_LEVEL_HIGH>;
			interrupt-names = "tei", "ri", "ti", "spi", "sti",
					  "naki", "ali", "tmoi";
			clocks = <&cpg CPG_MOD 0x98>;
			resets = <&cpg 0x9c>;
			power-domains = <&cpg>;
			#address-cells = <1>;
			#size-cells = <0>;
			status = "disabled";
		};

		i2c5: i2c@14401800 {
			compatible = "renesas,riic-r9a09g056", "renesas,riic-r9a09g057";
			reg = <0 0x14401800 0 0x400>;
			interrupts = <GIC_SPI 204 IRQ_TYPE_LEVEL_HIGH>,
				     <GIC_SPI 517 IRQ_TYPE_EDGE_RISING>,
				     <GIC_SPI 516 IRQ_TYPE_EDGE_RISING>,
				     <GIC_SPI 206 IRQ_TYPE_LEVEL_HIGH>,
				     <GIC_SPI 207 IRQ_TYPE_LEVEL_HIGH>,
				     <GIC_SPI 205 IRQ_TYPE_LEVEL_HIGH>,
				     <GIC_SPI 208 IRQ_TYPE_LEVEL_HIGH>,
				     <GIC_SPI 209 IRQ_TYPE_LEVEL_HIGH>;
			interrupt-names = "tei", "ri", "ti", "spi", "sti",
					  "naki", "ali", "tmoi";
			clocks = <&cpg CPG_MOD 0x99>;
			resets = <&cpg 0x9d>;
			power-domains = <&cpg>;
			#address-cells = <1>;
			#size-cells = <0>;
			status = "disabled";
		};

		i2c6: i2c@14401c00 {
			compatible = "renesas,riic-r9a09g056", "renesas,riic-r9a09g057";
			reg = <0 0x14401c00 0 0x400>;
			interrupts = <GIC_SPI 210 IRQ_TYPE_LEVEL_HIGH>,
				     <GIC_SPI 519 IRQ_TYPE_EDGE_RISING>,
				     <GIC_SPI 518 IRQ_TYPE_EDGE_RISING>,
				     <GIC_SPI 212 IRQ_TYPE_LEVEL_HIGH>,
				     <GIC_SPI 213 IRQ_TYPE_LEVEL_HIGH>,
				     <GIC_SPI 211 IRQ_TYPE_LEVEL_HIGH>,
				     <GIC_SPI 214 IRQ_TYPE_LEVEL_HIGH>,
				     <GIC_SPI 215 IRQ_TYPE_LEVEL_HIGH>;
			interrupt-names = "tei", "ri", "ti", "spi", "sti",
					  "naki", "ali", "tmoi";
			clocks = <&cpg CPG_MOD 0x9a>;
			resets = <&cpg 0x9e>;
			power-domains = <&cpg>;
			#address-cells = <1>;
			#size-cells = <0>;
			status = "disabled";
		};

		i2c7: i2c@14402000 {
			compatible = "renesas,riic-r9a09g056", "renesas,riic-r9a09g057";
			reg = <0 0x14402000 0 0x400>;
			interrupts = <GIC_SPI 216 IRQ_TYPE_LEVEL_HIGH>,
				     <GIC_SPI 521 IRQ_TYPE_EDGE_RISING>,
				     <GIC_SPI 520 IRQ_TYPE_EDGE_RISING>,
				     <GIC_SPI 218 IRQ_TYPE_LEVEL_HIGH>,
				     <GIC_SPI 219 IRQ_TYPE_LEVEL_HIGH>,
				     <GIC_SPI 217 IRQ_TYPE_LEVEL_HIGH>,
				     <GIC_SPI 220 IRQ_TYPE_LEVEL_HIGH>,
				     <GIC_SPI 221 IRQ_TYPE_LEVEL_HIGH>;
			interrupt-names = "tei", "ri", "ti", "spi", "sti",
					  "naki", "ali", "tmoi";
			clocks = <&cpg CPG_MOD 0x9b>;
			resets = <&cpg 0x9f>;
			power-domains = <&cpg>;
			#address-cells = <1>;
			#size-cells = <0>;
			status = "disabled";
		};

		i2c8: i2c@11c01000 {
			compatible = "renesas,riic-r9a09g056", "renesas,riic-r9a09g057";
			reg = <0 0x11c01000 0 0x400>;
			interrupts = <GIC_SPI 222 IRQ_TYPE_LEVEL_HIGH>,
				     <GIC_SPI 523 IRQ_TYPE_EDGE_RISING>,
				     <GIC_SPI 522 IRQ_TYPE_EDGE_RISING>,
				     <GIC_SPI 224 IRQ_TYPE_LEVEL_HIGH>,
				     <GIC_SPI 225 IRQ_TYPE_LEVEL_HIGH>,
				     <GIC_SPI 223 IRQ_TYPE_LEVEL_HIGH>,
				     <GIC_SPI 226 IRQ_TYPE_LEVEL_HIGH>,
				     <GIC_SPI 227 IRQ_TYPE_LEVEL_HIGH>;
			interrupt-names = "tei", "ri", "ti", "spi", "sti",
					  "naki", "ali", "tmoi";
			clocks = <&cpg CPG_MOD 0x93>;
			resets = <&cpg 0xa0>;
			power-domains = <&cpg>;
			#address-cells = <1>;
			#size-cells = <0>;
			status = "disabled";
		};

		sci0: serial@12800c00 {
			compatible = "renesas,r9a09g056-rz-rsci",
				     "renesas,rz-rscif";
			reg = <0 0x12800c00 0 0x400>;
			interrupts = <GIC_SPI 114 IRQ_TYPE_LEVEL_HIGH>,
				     <GIC_SPI 115 IRQ_TYPE_EDGE_RISING>,
				     <GIC_SPI 116 IRQ_TYPE_EDGE_RISING>,
				     <GIC_SPI 117 IRQ_TYPE_LEVEL_HIGH>;
			interrupt-names = "eri", "rxi", "txi", "tei";
			clocks = <&cpg CPG_MOD 0x5d>, <&cpg CPG_MOD 0x5e>;
			clock-names = "fck", "tclk";
			power-domains = <&cpg>;
			resets = <&cpg 0x81>, <&cpg 0x82>;
			reset-names = "presetn", "tresetn";
			status = "disabled";
		};

		sci1: serial@12801000 {
			compatible = "renesas,r9a09g056-rz-rsci",
				     "renesas,rz-rscif";
			reg = <0 0x12801000 0 0x400>;
			interrupts = <GIC_SPI 120 IRQ_TYPE_LEVEL_HIGH>,
				     <GIC_SPI 121 IRQ_TYPE_EDGE_RISING>,
				     <GIC_SPI 122 IRQ_TYPE_EDGE_RISING>,
				     <GIC_SPI 123 IRQ_TYPE_LEVEL_HIGH>;
			interrupt-names = "eri", "rxi", "txi", "tei";
			clocks = <&cpg CPG_MOD 0x62>, <&cpg CPG_MOD 0x63>;
			clock-names = "fck", "tclk";
			power-domains = <&cpg>;
			resets = <&cpg 0x83>, <&cpg 0x84>;
			reset-names = "presetn", "tresetn";
			status = "disabled";
		};

		sci2: serial@12801400 {
			compatible = "renesas,r9a09g056-rz-rsci",
				     "renesas,rz-rscif";
			reg = <0 0x12801400 0 0x400>;
			interrupts = <GIC_SPI 126 IRQ_TYPE_LEVEL_HIGH>,
				     <GIC_SPI 127 IRQ_TYPE_EDGE_RISING>,
				     <GIC_SPI 128 IRQ_TYPE_EDGE_RISING>,
				     <GIC_SPI 129 IRQ_TYPE_LEVEL_HIGH>;
			interrupt-names = "eri", "rxi", "txi", "tei";
			clocks = <&cpg CPG_MOD 0x67>, <&cpg CPG_MOD 0x68>;
			clock-names = "fck", "tclk";
			power-domains = <&cpg>;
			resets = <&cpg 0x85>, <&cpg 0x86>;
			reset-names = "presetn", "tresetn";
			status = "disabled";
		};

		sci3: serial@12801800 {
			compatible = "renesas,r9a09g056-rz-rsci",
				     "renesas,rz-rscif";
			reg = <0 0x12801800 0 0x400>;
			interrupts = <GIC_SPI 132 IRQ_TYPE_LEVEL_HIGH>,
				     <GIC_SPI 133 IRQ_TYPE_EDGE_RISING>,
				     <GIC_SPI 134 IRQ_TYPE_EDGE_RISING>,
				     <GIC_SPI 135 IRQ_TYPE_LEVEL_HIGH>;
			interrupt-names = "eri", "rxi", "txi", "tei";
			clocks = <&cpg CPG_MOD 0x6c>, <&cpg CPG_MOD 0x6d>;
			clock-names = "fck", "tclk";
			power-domains = <&cpg>;
			resets = <&cpg 0x87>, <&cpg 0x88>;
			reset-names = "presetn", "tresetn";
			status = "disabled";
		};

		sci4: serial@12801c00 {
			compatible = "renesas,r9a09g056-rz-rsci",
				     "renesas,rz-rscif";
			reg = <0 0x12801c00 0 0x400>;
			interrupts = <GIC_SPI 138 IRQ_TYPE_LEVEL_HIGH>,
				     <GIC_SPI 139 IRQ_TYPE_EDGE_RISING>,
				     <GIC_SPI 140 IRQ_TYPE_EDGE_RISING>,
				     <GIC_SPI 141 IRQ_TYPE_LEVEL_HIGH>;
			interrupt-names = "eri", "rxi", "txi", "tei";
			clocks = <&cpg CPG_MOD 0x71>, <&cpg CPG_MOD 0x72>;
			clock-names = "fck", "tclk";
			power-domains = <&cpg>;
			resets = <&cpg 0x89>, <&cpg 0x8a>;
			reset-names = "presetn", "tresetn";
			status = "disabled";
		};

		sci5: serial@12802000 {
			compatible = "renesas,r9a09g056-rz-rsci",
				     "renesas,rz-rscif";
			reg = <0 0x12802000 0 0x400>;
			interrupts = <GIC_SPI 144 IRQ_TYPE_LEVEL_HIGH>,
				     <GIC_SPI 145 IRQ_TYPE_EDGE_RISING>,
				     <GIC_SPI 146 IRQ_TYPE_EDGE_RISING>,
				     <GIC_SPI 147 IRQ_TYPE_LEVEL_HIGH>;
			interrupt-names = "eri", "rxi", "txi", "tei";
			clocks = <&cpg CPG_MOD 0x76>, <&cpg CPG_MOD 0x77>;
			clock-names = "fck", "tclk";
			power-domains = <&cpg>;
			resets = <&cpg 0x8b>, <&cpg 0x8c>;
			reset-names = "presetn", "tresetn";
			status = "disabled";
		};

		sci6: serial@12802400 {
			compatible = "renesas,r9a09g056-rz-rsci",
				     "renesas,rz-rscif";
			reg = <0 0x12802400 0 0x400>;
			interrupts = <GIC_SPI 150 IRQ_TYPE_LEVEL_HIGH>,
				     <GIC_SPI 151 IRQ_TYPE_EDGE_RISING>,
				     <GIC_SPI 152 IRQ_TYPE_EDGE_RISING>,
				     <GIC_SPI 153 IRQ_TYPE_LEVEL_HIGH>;
			interrupt-names = "eri", "rxi", "txi", "tei";
			clocks = <&cpg CPG_MOD 0x7b>, <&cpg CPG_MOD 0x7c>;
			clock-names = "fck", "tclk";
			power-domains = <&cpg>;
			resets = <&cpg 0x8d>, <&cpg 0x8e>;
			reset-names = "presetn", "tresetn";
			status = "disabled";
		};

		sci7: serial@12802800 {
			compatible = "renesas,r9a09g056-rz-rsci",
				     "renesas,rz-rscif";
			reg = <0 0x12802800 0 0x400>;
			interrupts = <GIC_SPI 156 IRQ_TYPE_LEVEL_HIGH>,
				     <GIC_SPI 157 IRQ_TYPE_EDGE_RISING>,
				     <GIC_SPI 158 IRQ_TYPE_EDGE_RISING>,
				     <GIC_SPI 159 IRQ_TYPE_LEVEL_HIGH>;
			interrupt-names = "eri", "rxi", "txi", "tei";
			clocks = <&cpg CPG_MOD 0x80>, <&cpg CPG_MOD 0x81>;
			clock-names = "fck", "tclk";
			power-domains = <&cpg>;
			resets = <&cpg 0x8f>, <&cpg 0x90>;
			reset-names = "presetn", "tresetn";
			status = "disabled";
		};

		sci8: serial@12802c00 {
			compatible = "renesas,r9a09g056-rz-rsci",
				     "renesas,rz-rscif";
			reg = <0 0x12802c00 0 0x400>;
			interrupts = <GIC_SPI 162 IRQ_TYPE_LEVEL_HIGH>,
				     <GIC_SPI 163 IRQ_TYPE_EDGE_RISING>,
				     <GIC_SPI 164 IRQ_TYPE_EDGE_RISING>,
				     <GIC_SPI 165 IRQ_TYPE_LEVEL_HIGH>;
			interrupt-names = "eri", "rxi", "txi", "tei";
			clocks = <&cpg CPG_MOD 0x85>, <&cpg CPG_MOD 0x86>;
			clock-names = "fck", "tclk";
			power-domains = <&cpg>;
			resets = <&cpg 0x91>, <&cpg 0x92>;
			reset-names = "presetn", "tresetn";
			status = "disabled";
		};

		sci9: serial@12803000 {
			compatible = "renesas,r9a09g056-rz-rsci",
				     "renesas,rz-rscif";
			reg = <0 0x12803000 0 0x400>;
			interrupts = <GIC_SPI 168 IRQ_TYPE_LEVEL_HIGH>,
				     <GIC_SPI 169 IRQ_TYPE_EDGE_RISING>,
				     <GIC_SPI 170 IRQ_TYPE_EDGE_RISING>,
				     <GIC_SPI 171 IRQ_TYPE_LEVEL_HIGH>;
			interrupt-names = "eri", "rxi", "txi", "tei";
			clocks = <&cpg CPG_MOD 0x8a>, <&cpg CPG_MOD 0x8b>;
			clock-names = "fck", "tclk";
			power-domains = <&cpg>;
			resets = <&cpg 0x93>, <&cpg 0x94>;
			reset-names = "presetn", "tresetn";
			status = "disabled";
		};

		rsci_i2c0: i2c@12800c00 {
			compatible = "renesas,r9a09g056-rz-rsci-i2c",
				     "renesas,rsci-i2c";
			reg = <0 0x12800c00 0 0x400>;
			interrupts = <GIC_SPI 114 IRQ_TYPE_LEVEL_HIGH>,
				     <GIC_SPI 115 IRQ_TYPE_EDGE_RISING>,
				     <GIC_SPI 116 IRQ_TYPE_EDGE_RISING>,
				     <GIC_SPI 117 IRQ_TYPE_LEVEL_HIGH>;
			interrupt-names = "eri", "rxi", "txi", "tei";
			clocks = <&cpg CPG_MOD 0x5d>, <&cpg CPG_MOD 0x5e>;
			clock-names = "fck", "tclk";
			power-domains = <&cpg>;
			resets = <&cpg 0x81>, <&cpg 0x82>;
			reset-names = "presetn", "tresetn";
			status = "disabled";
		};

		rsci_i2c1: i2c@12801000 {
			compatible = "renesas,r9a09g056-rz-rsci-i2c",
				     "renesas,rsci-i2c";
			reg = <0 0x12801000 0 0x400>;
			interrupts = <GIC_SPI 120 IRQ_TYPE_LEVEL_HIGH>,
				     <GIC_SPI 121 IRQ_TYPE_EDGE_RISING>,
				     <GIC_SPI 122 IRQ_TYPE_EDGE_RISING>,
				     <GIC_SPI 123 IRQ_TYPE_LEVEL_HIGH>;
			interrupt-names = "eri", "rxi", "txi", "tei";
			clocks = <&cpg CPG_MOD 0x62>, <&cpg CPG_MOD 0x63>;
			clock-names = "fck", "tclk";
			power-domains = <&cpg>;
			resets = <&cpg 0x83>, <&cpg 0x84>;
			reset-names = "presetn", "tresetn";
			status = "disabled";
		};

		rsci_i2c2: i2c@12801400 {
			compatible = "renesas,r9a09g056-rz-rsci-i2c",
				     "renesas,rsci-i2c";
			reg = <0 0x12801400 0 0x400>;
			interrupts = <GIC_SPI 126 IRQ_TYPE_LEVEL_HIGH>,
				     <GIC_SPI 127 IRQ_TYPE_EDGE_RISING>,
				     <GIC_SPI 128 IRQ_TYPE_EDGE_RISING>,
				     <GIC_SPI 129 IRQ_TYPE_LEVEL_HIGH>;
			interrupt-names = "eri", "rxi", "txi", "tei";
			clocks = <&cpg CPG_MOD 0x67>, <&cpg CPG_MOD 0x68>;
			clock-names = "fck", "tclk";
			power-domains = <&cpg>;
			resets = <&cpg 0x85>, <&cpg 0x86>;
			reset-names = "presetn", "tresetn";
			status = "disabled";
		};

		rsci_i2c3: i2c@12801800 {
			compatible = "renesas,r9a09g056-rz-rsci-i2c",
				     "renesas,rsci-i2c";
			reg = <0 0x12801800 0 0x400>;
			interrupts = <GIC_SPI 132 IRQ_TYPE_LEVEL_HIGH>,
				     <GIC_SPI 133 IRQ_TYPE_EDGE_RISING>,
				     <GIC_SPI 134 IRQ_TYPE_EDGE_RISING>,
				     <GIC_SPI 135 IRQ_TYPE_LEVEL_HIGH>;
			interrupt-names = "eri", "rxi", "txi", "tei";
			clocks = <&cpg CPG_MOD 0x6c>, <&cpg CPG_MOD 0x6d>;
			clock-names = "fck", "tclk";
			power-domains = <&cpg>;
			resets = <&cpg 0x87>, <&cpg 0x88>;
			reset-names = "presetn", "tresetn";
			status = "disabled";
		};

		rsci_i2c4: i2c@12801c00 {
			compatible = "renesas,r9a09g056-rz-rsci-i2c",
				     "renesas,rsci-i2c";
			reg = <0 0x12801c00 0 0x400>;
			interrupts = <GIC_SPI 138 IRQ_TYPE_LEVEL_HIGH>,
				     <GIC_SPI 139 IRQ_TYPE_EDGE_RISING>,
				     <GIC_SPI 140 IRQ_TYPE_EDGE_RISING>,
				     <GIC_SPI 141 IRQ_TYPE_LEVEL_HIGH>;
			interrupt-names = "eri", "rxi", "txi", "tei";
			clocks = <&cpg CPG_MOD 0x71>, <&cpg CPG_MOD 0x72>;
			clock-names = "fck", "tclk";
			power-domains = <&cpg>;
			resets = <&cpg 0x89>, <&cpg 0x8a>;
			reset-names = "presetn", "tresetn";
			status = "disabled";
		};

		rsci_i2c5: i2c@12802000 {
			compatible = "renesas,r9a09g056-rz-rsci-i2c",
				     "renesas,rsci-i2c";
			reg = <0 0x12802000 0 0x400>;
			interrupts = <GIC_SPI 144 IRQ_TYPE_LEVEL_HIGH>,
				     <GIC_SPI 145 IRQ_TYPE_EDGE_RISING>,
				     <GIC_SPI 146 IRQ_TYPE_EDGE_RISING>,
				     <GIC_SPI 147 IRQ_TYPE_LEVEL_HIGH>;
			interrupt-names = "eri", "rxi", "txi", "tei";
			clocks = <&cpg CPG_MOD 0x76>, <&cpg CPG_MOD 0x77>;
			clock-names = "fck", "tclk";
			power-domains = <&cpg>;
			resets = <&cpg 0x8b>, <&cpg 0x8c>;
			reset-names = "presetn", "tresetn";
			status = "disabled";
		};

		rsci_i2c6: i2c@12802400 {
			compatible = "renesas,r9a09g056-rz-rsci-i2c",
				     "renesas,rsci-i2c";
			reg = <0 0x12802400 0 0x400>;
			interrupts = <GIC_SPI 150 IRQ_TYPE_LEVEL_HIGH>,
				     <GIC_SPI 151 IRQ_TYPE_EDGE_RISING>,
				     <GIC_SPI 152 IRQ_TYPE_EDGE_RISING>,
				     <GIC_SPI 153 IRQ_TYPE_LEVEL_HIGH>;
			interrupt-names = "eri", "rxi", "txi", "tei";
			clocks = <&cpg CPG_MOD 0x7b>, <&cpg CPG_MOD 0x7c>;
			clock-names = "fck", "tclk";
			power-domains = <&cpg>;
			resets = <&cpg 0x8d>, <&cpg 0x8e>;
			reset-names = "presetn", "tresetn";
			status = "disabled";
		};

		rsci_i2c7: i2c@12802800 {
			compatible = "renesas,r9a09g056-rz-rsci-i2c",
				     "renesas,rsci-i2c";
			reg = <0 0x12802800 0 0x400>;
			interrupts = <GIC_SPI 156 IRQ_TYPE_LEVEL_HIGH>,
				     <GIC_SPI 157 IRQ_TYPE_EDGE_RISING>,
				     <GIC_SPI 158 IRQ_TYPE_EDGE_RISING>,
				     <GIC_SPI 159 IRQ_TYPE_LEVEL_HIGH>;
			interrupt-names = "eri", "rxi", "txi", "tei";
			clocks = <&cpg CPG_MOD 0x80>, <&cpg CPG_MOD 0x81>;
			clock-names = "fck", "tclk";
			power-domains = <&cpg>;
			resets = <&cpg 0x8f>, <&cpg 0x90>;
			reset-names = "presetn", "tresetn";
			status = "disabled";
		};

		rsci_i2c8: i2c@12802c00 {
			compatible = "renesas,r9a09g056-rz-rsci-i2c",
				     "renesas,rsci-i2c";
			reg = <0 0x12802c00 0 0x400>;
			interrupts = <GIC_SPI 162 IRQ_TYPE_LEVEL_HIGH>,
				     <GIC_SPI 163 IRQ_TYPE_EDGE_RISING>,
				     <GIC_SPI 164 IRQ_TYPE_EDGE_RISING>,
				     <GIC_SPI 165 IRQ_TYPE_LEVEL_HIGH>;
			interrupt-names = "eri", "rxi", "txi", "tei";
			clocks = <&cpg CPG_MOD 0x85>, <&cpg CPG_MOD 0x86>;
			clock-names = "fck", "tclk";
			power-domains = <&cpg>;
			resets = <&cpg 0x91>, <&cpg 0x92>;
			reset-names = "presetn", "tresetn";
			status = "disabled";
		};

		rsci_i2c9: i2c@12803000 {
			compatible = "renesas,r9a09g056-rz-rsci-i2c",
				     "renesas,rsci-i2c";
			reg = <0 0x12803000 0 0x400>;
			interrupts = <GIC_SPI 168 IRQ_TYPE_LEVEL_HIGH>,
				     <GIC_SPI 169 IRQ_TYPE_EDGE_RISING>,
				     <GIC_SPI 170 IRQ_TYPE_EDGE_RISING>,
				     <GIC_SPI 171 IRQ_TYPE_LEVEL_HIGH>;
			interrupt-names = "eri", "rxi", "txi", "tei";
			clocks = <&cpg CPG_MOD 0x8a>, <&cpg CPG_MOD 0x8b>;
			clock-names = "fck", "tclk";
			power-domains = <&cpg>;
			resets = <&cpg 0x93>, <&cpg 0x94>;
			reset-names = "presetn", "tresetn";
			status = "disabled";
		};

		rsci_spi0: spi@12800c00 {
			compatible = "renesas,r9a09g056-rz-rsci-spi",
				     "renesas,rsci-spi";
			reg = <0 0x12800c00 0 0x400>;
			interrupts = <GIC_SPI 114 IRQ_TYPE_LEVEL_HIGH>,
				     <GIC_SPI 115 IRQ_TYPE_EDGE_RISING>,
				     <GIC_SPI 116 IRQ_TYPE_EDGE_RISING>,
				     <GIC_SPI 117 IRQ_TYPE_LEVEL_HIGH>;
			interrupt-names = "eri", "rxi", "txi", "tei";
			clocks = <&cpg CPG_MOD 0x5d>, <&cpg CPG_MOD 0x5e>;
			clock-names = "fck", "tclk";
			power-domains = <&cpg>;
			resets = <&cpg 0x81>, <&cpg 0x82>;
			reset-names = "presetn", "tresetn";
			num-cs = <1>;
			#address-cells = <1>;
			#size-cells = <0>;
			status = "disabled";
		};

		rsci_spi1: spi@12801000 {
			compatible = "renesas,r9a09g056-rz-rsci-spi",
				     "renesas,rsci-spi";
			reg = <0 0x12801000 0 0x400>;
			interrupts = <GIC_SPI 120 IRQ_TYPE_LEVEL_HIGH>,
				     <GIC_SPI 121 IRQ_TYPE_EDGE_RISING>,
				     <GIC_SPI 122 IRQ_TYPE_EDGE_RISING>,
				     <GIC_SPI 123 IRQ_TYPE_LEVEL_HIGH>;
			interrupt-names = "eri", "rxi", "txi", "tei";
			clocks = <&cpg CPG_MOD 0x62>, <&cpg CPG_MOD 0x63>;
			clock-names = "fck", "tclk";
			power-domains = <&cpg>;
			resets = <&cpg 0x83>, <&cpg 0x84>;
			reset-names = "presetn", "tresetn";
			num-cs = <1>;
			#address-cells = <1>;
			#size-cells = <0>;
			status = "disabled";
		};

		rsci_spi2: spi@12801400 {
			compatible = "renesas,r9a09g056-rz-rsci-spi",
				     "renesas,rsci-spi";
			reg = <0 0x12801400 0 0x400>;
			interrupts = <GIC_SPI 126 IRQ_TYPE_LEVEL_HIGH>,
				     <GIC_SPI 127 IRQ_TYPE_EDGE_RISING>,
				     <GIC_SPI 128 IRQ_TYPE_EDGE_RISING>,
				     <GIC_SPI 129 IRQ_TYPE_LEVEL_HIGH>;
			interrupt-names = "eri", "rxi", "txi", "tei";
			clocks = <&cpg CPG_MOD 0x67>, <&cpg CPG_MOD 0x68>;
			clock-names = "fck", "tclk";
			power-domains = <&cpg>;
			resets = <&cpg 0x85>, <&cpg 0x86>;
			reset-names = "presetn", "tresetn";
			num-cs = <1>;
			#address-cells = <1>;
			#size-cells = <0>;
			status = "disabled";
		};

		rsci_spi3: spi@12801800 {
			compatible = "renesas,r9a09g056-rz-rsci-spi",
				     "renesas,rsci-spi";
			reg = <0 0x12801800 0 0x400>;
			interrupts = <GIC_SPI 132 IRQ_TYPE_LEVEL_HIGH>,
				     <GIC_SPI 133 IRQ_TYPE_EDGE_RISING>,
				     <GIC_SPI 134 IRQ_TYPE_EDGE_RISING>,
				     <GIC_SPI 135 IRQ_TYPE_LEVEL_HIGH>;
			interrupt-names = "eri", "rxi", "txi", "tei";
			clocks = <&cpg CPG_MOD 0x6c>, <&cpg CPG_MOD 0x6d>;
			clock-names = "fck", "tclk";
			power-domains = <&cpg>;
			resets = <&cpg 0x87>, <&cpg 0x88>;
			reset-names = "presetn", "tresetn";
			num-cs = <1>;
			#address-cells = <1>;
			#size-cells = <0>;
			status = "disabled";
		};

		rsci_spi4: spi@12801c00 {
			compatible = "renesas,r9a09g056-rz-rsci-spi",
				     "renesas,rsci-spi";
			reg = <0 0x12801c00 0 0x400>;
			interrupts = <GIC_SPI 138 IRQ_TYPE_LEVEL_HIGH>,
				     <GIC_SPI 139 IRQ_TYPE_EDGE_RISING>,
				     <GIC_SPI 140 IRQ_TYPE_EDGE_RISING>,
				     <GIC_SPI 141 IRQ_TYPE_LEVEL_HIGH>;
			interrupt-names = "eri", "rxi", "txi", "tei";
			clocks = <&cpg CPG_MOD 0x71>, <&cpg CPG_MOD 0x72>;
			clock-names = "fck", "tclk";
			power-domains = <&cpg>;
			resets = <&cpg 0x89>, <&cpg 0x8a>;
			reset-names = "presetn", "tresetn";
			num-cs = <1>;
			#address-cells = <1>;
			#size-cells = <0>;
			status = "disabled";
		};

		rsci_spi5: spi@12802000 {
			compatible = "renesas,r9a09g056-rz-rsci-spi",
				     "renesas,rsci-spi";
			reg = <0 0x12802000 0 0x400>;
			interrupts = <GIC_SPI 144 IRQ_TYPE_LEVEL_HIGH>,
				     <GIC_SPI 145 IRQ_TYPE_EDGE_RISING>,
				     <GIC_SPI 146 IRQ_TYPE_EDGE_RISING>,
				     <GIC_SPI 147 IRQ_TYPE_LEVEL_HIGH>;
			interrupt-names = "eri", "rxi", "txi", "tei";
			clocks = <&cpg CPG_MOD 0x76>, <&cpg CPG_MOD 0x77>;
			clock-names = "fck", "tclk";
			power-domains = <&cpg>;
			resets = <&cpg 0x8b>, <&cpg 0x8c>;
			reset-names = "presetn", "tresetn";
			num-cs = <1>;
			#address-cells = <1>;
			#size-cells = <0>;
			status = "disabled";
		};

		rsci_spi6: spi@12802400 {
			compatible = "renesas,r9a09g056-rz-rsci-spi",
				     "renesas,rsci-spi";
			reg = <0 0x12802400 0 0x400>;
			interrupts = <GIC_SPI 150 IRQ_TYPE_LEVEL_HIGH>,
				     <GIC_SPI 151 IRQ_TYPE_EDGE_RISING>,
				     <GIC_SPI 152 IRQ_TYPE_EDGE_RISING>,
				     <GIC_SPI 153 IRQ_TYPE_LEVEL_HIGH>;
			interrupt-names = "eri", "rxi", "txi", "tei";
			clocks = <&cpg CPG_MOD 0x7b>, <&cpg CPG_MOD 0x7c>;
			clock-names = "fck", "tclk";
			power-domains = <&cpg>;
			resets = <&cpg 0x8d>, <&cpg 0x8e>;
			reset-names = "presetn", "tresetn";
			num-cs = <1>;
			#address-cells = <1>;
			#size-cells = <0>;
			status = "disabled";
		};

		rsci_spi7: spi@12802800 {
			compatible = "renesas,r9a09g056-rz-rsci-spi",
				     "renesas,rsci-spi";
			reg = <0 0x12802800 0 0x400>;
			interrupts = <GIC_SPI 156 IRQ_TYPE_LEVEL_HIGH>,
				     <GIC_SPI 157 IRQ_TYPE_EDGE_RISING>,
				     <GIC_SPI 158 IRQ_TYPE_EDGE_RISING>,
				     <GIC_SPI 159 IRQ_TYPE_LEVEL_HIGH>;
			interrupt-names = "eri", "rxi", "txi", "tei";
			clocks = <&cpg CPG_MOD 0x80>, <&cpg CPG_MOD 0x81>;
			clock-names = "fck", "tclk";
			power-domains = <&cpg>;
			resets = <&cpg 0x8f>, <&cpg 0x90>;
			reset-names = "presetn", "tresetn";
			num-cs = <1>;
			#address-cells = <1>;
			#size-cells = <0>;
			status = "disabled";
		};

		rsci_spi8: spi@12802c00 {
			compatible = "renesas,r9a09g056-rz-rsci-spi",
				     "renesas,rsci-spi";
			reg = <0 0x12802c00 0 0x400>;
			interrupts = <GIC_SPI 162 IRQ_TYPE_LEVEL_HIGH>,
				     <GIC_SPI 163 IRQ_TYPE_EDGE_RISING>,
				     <GIC_SPI 164 IRQ_TYPE_EDGE_RISING>,
				     <GIC_SPI 165 IRQ_TYPE_LEVEL_HIGH>;
			interrupt-names = "eri", "rxi", "txi", "tei";
			clocks = <&cpg CPG_MOD 0x85>, <&cpg CPG_MOD 0x86>;
			clock-names = "fck", "tclk";
			power-domains = <&cpg>;
			resets = <&cpg 0x91>, <&cpg 0x92>;
			reset-names = "presetn", "tresetn";
			num-cs = <1>;
			#address-cells = <1>;
			#size-cells = <0>;
			status = "disabled";
		};

		rsci_spi9: spi@12803000 {
			compatible = "renesas,r9a09g056-rz-rsci-spi",
				     "renesas,rsci-spi";
			reg = <0 0x12803000 0 0x400>;
			interrupts = <GIC_SPI 168 IRQ_TYPE_LEVEL_HIGH>,
				     <GIC_SPI 169 IRQ_TYPE_EDGE_RISING>,
				     <GIC_SPI 170 IRQ_TYPE_EDGE_RISING>,
				     <GIC_SPI 171 IRQ_TYPE_LEVEL_HIGH>;
			interrupt-names = "eri", "rxi", "txi", "tei";
			clocks = <&cpg CPG_MOD 0x8a>, <&cpg CPG_MOD 0x8b>;
			clock-names = "fck", "tclk";
			power-domains = <&cpg>;
			resets = <&cpg 0x93>, <&cpg 0x94>;
			reset-names = "presetn", "tresetn";
			num-cs = <1>;
			#address-cells = <1>;
			#size-cells = <0>;
			status = "disabled";
		};

		gpu: gpu@14850000 {
			compatible = "renesas,r9a09g056-mali",
				     "arm,mali-bifrost";
			reg = <0x0 0x14850000 0x0 0x10000>;
			interrupts = <GIC_SPI 884 IRQ_TYPE_LEVEL_HIGH>,
				     <GIC_SPI 885 IRQ_TYPE_LEVEL_HIGH>,
				     <GIC_SPI 883 IRQ_TYPE_LEVEL_HIGH>,
				     <GIC_SPI 886 IRQ_TYPE_LEVEL_HIGH>;
			interrupt-names = "job", "mmu", "gpu", "event";
			clocks = <&cpg CPG_MOD 0xf0>,
				 <&cpg CPG_MOD 0xf1>,
				 <&cpg CPG_MOD 0xf2>;
			clock-names = "gpu", "bus", "bus_ace";
			resets = <&cpg 0xdd>,
				 <&cpg 0xde>,
				 <&cpg 0xdf>;
			reset-names = "rst", "axi_rst", "ace_rst";
			power-domains = <&cpg>;
			operating-points-v2 = <&gpu_opp_table>;
			status = "disabled";
		};

		i3c: i3c-master@12400000 {
			compatible = "renesas,i3c-master";
			reg = <0 0x12400000 0 0x10000>;
			clocks = <&cpg CPG_MOD 0x90>,
				 <&cpg CPG_MOD 0x91>,
				 <&cpg CPG_MOD 0x92>;
			clock-names = "pclkrw", "pclk", "tclk";
			interrupts = <GIC_SPI 674 IRQ_TYPE_LEVEL_HIGH>,
				     <GIC_SPI 675 IRQ_TYPE_LEVEL_HIGH>,
				     <GIC_SPI 676 IRQ_TYPE_LEVEL_HIGH>,
				     <GIC_SPI 677 IRQ_TYPE_EDGE_RISING>,
				     <GIC_SPI 678 IRQ_TYPE_EDGE_RISING>,
				     <GIC_SPI 679 IRQ_TYPE_EDGE_RISING>,
				     <GIC_SPI 680 IRQ_TYPE_EDGE_RISING>,
				     <GIC_SPI 681 IRQ_TYPE_EDGE_RISING>,
				     <GIC_SPI 682 IRQ_TYPE_EDGE_RISING>,
				     <GIC_SPI 689 IRQ_TYPE_LEVEL_HIGH>,
				     <GIC_SPI 690 IRQ_TYPE_LEVEL_HIGH>,
				     <GIC_SPI 692 IRQ_TYPE_LEVEL_HIGH>,
				     <GIC_SPI 693 IRQ_TYPE_LEVEL_HIGH>,
				     <GIC_SPI 694 IRQ_TYPE_LEVEL_HIGH>,
				     <GIC_SPI 695 IRQ_TYPE_LEVEL_HIGH>,
				     <GIC_SPI 696 IRQ_TYPE_LEVEL_HIGH>;
			interrupt-names = "ierr", "terr", "abort", "resp",
					  "cmd", "ibi", "rx", "tx", "rcv",
					  "st", "sp", "tend", "nack",
					  "al", "tmo", "wu";
			resets = <&cpg 0x96>,
				 <&cpg 0x97>;
			reset-names = "presetn", "tresetn";
			#address-cells = <3>;
			#size-cells = <0>;
			i2c-scl-hz = <1000000>;
			i3c-scl-hz = <3000000>;
			status = "disabled";
		};

		gic: interrupt-controller@14900000 {
			compatible = "arm,gic-v3";
			reg = <0x0 0x14900000 0 0x20000>,
			      <0x0 0x14940000 0 0x80000>;
			#interrupt-cells = <3>;
			#address-cells = <0>;
			interrupt-controller;
			interrupts = <GIC_PPI 9 IRQ_TYPE_LEVEL_LOW>;
		};

		ohci0: usb@15800000 {
			compatible = "generic-ohci";
			reg = <0 0x15800000 0 0x100>;
			interrupts = <GIC_SPI 742 IRQ_TYPE_LEVEL_HIGH>;
			clocks = <&cpg CPG_MOD 0xb3>, <&cpg CPG_MOD 0xb6>;
			resets = <&usb20phyrst>, <&cpg 0xac>;
			phys = <&usb2_phy0 1>;
			phy-names = "usb";
			power-domains = <&cpg>;
			status = "disabled";
		};

		ehci0: usb@15800100 {
			compatible = "generic-ehci";
			reg = <0 0x15800100 0 0x100>;
			interrupts = <GIC_SPI 743 IRQ_TYPE_LEVEL_HIGH>;
			clocks = <&cpg CPG_MOD 0xb3>, <&cpg CPG_MOD 0xb6>;
			resets = <&usb20phyrst>, <&cpg 0xac>;
			phys = <&usb2_phy0 2>;
			phy-names = "usb";
			companion = <&ohci0>;
			power-domains = <&cpg>;
			status = "disabled";
		};

		usb2_phy0: usb-phy@15800200 {
			compatible = "renesas,usb2-phy-r9a09g056", "renesas,usb2-phy-r9a09g057";
			reg = <0 0x15800200 0 0x700>;
			interrupts = <GIC_SPI 745 IRQ_TYPE_LEVEL_HIGH>;
			clocks = <&cpg CPG_MOD 0xb3>,
				 <&cpg CPG_CORE R9A09G056_USB2_0_CLK_CORE0>;
			clock-names = "fck", "usb_x1";
			resets = <&usb20phyrst>;
			#phy-cells = <1>;
			power-domains = <&cpg>;
			status = "disabled";
		};

		hsusb: usb@15820000 {
			compatible = "renesas,usbhs-r9a09g056",
				     "renesas,rzg2l-usbhs";
			reg = <0 0x15820000 0 0x10000>;
			interrupts = <GIC_SPI 751 IRQ_TYPE_EDGE_RISING>,
				     <GIC_SPI 752 IRQ_TYPE_LEVEL_HIGH>,
				     <GIC_SPI 753 IRQ_TYPE_LEVEL_HIGH>,
				     <GIC_SPI 754 IRQ_TYPE_LEVEL_HIGH>;
			clocks = <&cpg CPG_MOD 0xb3>, <&cpg CPG_MOD 0xb5>;
			resets = <&usb20phyrst>,
				 <&cpg 0xae>;
			phys = <&usb2_phy0 3>;
			phy-names = "usb";
			power-domains = <&cpg>;
			status = "disabled";
		};

		usb20phyrst: usb20phy-reset@15830000 {
			compatible = "renesas,r9a09g056-usb2phy-reset",
				     "renesas,r9a09g057-usb2phy-reset";
			reg = <0 0x15830000 0 0x10000>;
			clocks = <&cpg CPG_MOD 0xb6>;
			resets = <&cpg 0xaf>;
			power-domains = <&cpg>;
			#reset-cells = <0>;
			status = "disabled";
		};

		canfd: can@12440000 {
			compatible = "renesas,r9a09g047-canfd";
			reg = <0 0x12440000 0 0x40000>;
			interrupts = <GIC_SPI 709 IRQ_TYPE_LEVEL_HIGH>,
				     <GIC_SPI 710 IRQ_TYPE_LEVEL_HIGH>,
				     <GIC_SPI 697 IRQ_TYPE_LEVEL_HIGH>,
				     <GIC_SPI 703 IRQ_TYPE_LEVEL_HIGH>,
				     <GIC_SPI 711 IRQ_TYPE_LEVEL_HIGH>,
				     <GIC_SPI 698 IRQ_TYPE_LEVEL_HIGH>,
				     <GIC_SPI 704 IRQ_TYPE_LEVEL_HIGH>,
				     <GIC_SPI 712 IRQ_TYPE_LEVEL_HIGH>,
				     <GIC_SPI 699 IRQ_TYPE_LEVEL_HIGH>,
				     <GIC_SPI 705 IRQ_TYPE_LEVEL_HIGH>,
				     <GIC_SPI 713 IRQ_TYPE_LEVEL_HIGH>,
				     <GIC_SPI 700 IRQ_TYPE_LEVEL_HIGH>,
				     <GIC_SPI 706 IRQ_TYPE_LEVEL_HIGH>,
				     <GIC_SPI 714 IRQ_TYPE_LEVEL_HIGH>,
				     <GIC_SPI 701 IRQ_TYPE_LEVEL_HIGH>,
				     <GIC_SPI 707 IRQ_TYPE_LEVEL_HIGH>,
				     <GIC_SPI 715 IRQ_TYPE_LEVEL_HIGH>,
				     <GIC_SPI 702 IRQ_TYPE_LEVEL_HIGH>,
				     <GIC_SPI 708 IRQ_TYPE_LEVEL_HIGH>,
				     <GIC_SPI 716 IRQ_TYPE_LEVEL_HIGH>;
			interrupt-names = "g_err", "g_recc",
					  "ch0_err", "ch0_rec", "ch0_trx",
					  "ch1_err", "ch1_rec", "ch1_trx",
					  "ch2_err", "ch2_rec", "ch2_trx",
					  "ch3_err", "ch3_rec", "ch3_trx",
					  "ch4_err", "ch4_rec", "ch4_trx",
					  "ch5_err", "ch5_rec", "ch5_trx";
			clocks = <&cpg CPG_MOD 0x9c>,
				 <&cpg CPG_MOD 0x9d>,
				 <&cpg CPG_MOD 0x9e>;
			clock-names = "fck", "ram_clk", "can_clk";
			resets = <&cpg 0xa1>, <&cpg 0xa2>;
			reset-names = "rstp_n", "rstc_n";
			power-domains = <&cpg>;
			status = "disabled";

			channel0 {
				status = "disabled";
			};
			channel1 {
				status = "disabled";
			};
			channel2 {
				status = "disabled";
			};
			channel3 {
				status = "disabled";
			};
			channel4 {
				status = "disabled";
			};
			channel5 {
				status = "disabled";
			};
		};

		usb3_phy0: usb-phy@15870000 {
			compatible = "renesas,usb3-phy-r9a09g056",
				     "renesas,rz-usb3-phy";
			reg = <0 0x15870000 0 0x10000>;
			clocks = <&cpg CPG_MOD 0xb0>,
				 <&cpg CPG_CORE R9A09G056_USB3_0_REF_ALT_CLK_P>,
				 <&cpg CPG_CORE R9A09G056_USB3_0_CLK_CORE>;
			power-domains = <&cpg>;
			resets = <&cpg 0xaa>;
			#phy-cells = <0>;
			status = "disabled";
		};

		xhci0: usb@15850000 {
			compatible = "renesas,rzv2h-xhci";
			reg = <0 0x15850000 0 0x10000>;
			interrupts = <GIC_SPI 759 IRQ_TYPE_LEVEL_HIGH>;
			clocks = <&cpg CPG_MOD 0xaf>;
			clock-names = "reg";
			power-domains = <&cpg>;
			resets = <&cpg 0xaa>;
			phys = <&usb3_phy0>;
			phy-names = "usb0";
			status = "disabled";
		};

		sdhi0: mmc@15c00000  {
			compatible = "renesas,sdhi-r9a09g056", "renesas,sdhi-r9a09g057";
			reg = <0x0 0x15c00000 0 0x10000>;
			interrupts = <GIC_SPI 735 IRQ_TYPE_LEVEL_HIGH>,
				     <GIC_SPI 736 IRQ_TYPE_LEVEL_HIGH>;
			clocks = <&cpg CPG_MOD 0xa3>, <&cpg CPG_MOD 0xa5>,
				 <&cpg CPG_MOD 0xa4>, <&cpg CPG_MOD 0xa6>;
			clock-names = "core", "clkh", "cd", "aclk";
			resets = <&cpg 0xa7>;
			power-domains = <&cpg>;
			status = "disabled";

			sdhi0_vqmmc: vqmmc-regulator {
				regulator-name = "SDHI0-VQMMC";
				regulator-min-microvolt = <1800000>;
				regulator-max-microvolt = <3300000>;
				status = "disabled";
			};
		};

		sdhi1: mmc@15c10000 {
			compatible = "renesas,sdhi-r9a09g056", "renesas,sdhi-r9a09g057";
			reg = <0x0 0x15c10000 0 0x10000>;
			interrupts = <GIC_SPI 737 IRQ_TYPE_LEVEL_HIGH>,
				     <GIC_SPI 738 IRQ_TYPE_LEVEL_HIGH>;
			clocks = <&cpg CPG_MOD 0xa7>, <&cpg CPG_MOD 0xa9>,
				 <&cpg CPG_MOD 0xa8>, <&cpg CPG_MOD 0xaa>;
			clock-names = "core", "clkh", "cd", "aclk";
			resets = <&cpg 0xa8>;
			power-domains = <&cpg>;
			status = "disabled";

			sdhi1_vqmmc: vqmmc-regulator {
				regulator-name = "SDHI1-VQMMC";
				regulator-min-microvolt = <1800000>;
				regulator-max-microvolt = <3300000>;
				status = "disabled";
			};
		};

		sdhi2: mmc@15c20000 {
			compatible = "renesas,sdhi-r9a09g056", "renesas,sdhi-r9a09g057";
			reg = <0x0 0x15c20000 0 0x10000>;
			interrupts = <GIC_SPI 739 IRQ_TYPE_LEVEL_HIGH>,
				     <GIC_SPI 740 IRQ_TYPE_LEVEL_HIGH>;
			clocks = <&cpg CPG_MOD 0xab>, <&cpg CPG_MOD 0xad>,
				 <&cpg CPG_MOD 0xac>, <&cpg CPG_MOD 0xae>;
			clock-names = "core", "clkh", "cd", "aclk";
			resets = <&cpg 0xa9>;
			power-domains = <&cpg>;
			status = "disabled";

			sdhi2_vqmmc: vqmmc-regulator {
				regulator-name = "SDHI2-VQMMC";
				regulator-min-microvolt = <1800000>;
				regulator-max-microvolt = <3300000>;
				status = "disabled";
			};
		};

		rtc: rtc@11c00800 {
			compatible = "renesas,r9a09g056-rtc", "renesas,rz-rtca3";
			reg = <0 0x11C00800 0 0x400>;
			interrupts = <GIC_SPI 525 IRQ_TYPE_EDGE_RISING>,
				     <GIC_SPI 526 IRQ_TYPE_EDGE_RISING>,
				     <GIC_SPI 524 IRQ_TYPE_EDGE_RISING>;
			interrupt-names = "period", "carry", "alarm";
			clocks = <&cpg CPG_MOD 0x53>, <&rtc_clk>;
			clock-names = "fck", "counter";
			resets = <&cpg 0x79>, <&cpg 0x7a>;
			reset-names = "rtc", "rtc_v";
			power-domains = <&cpg>;
			status = "disabled";
		};

		eth0: ethernet@15c30000 {
			compatible = "renesas,r9a09g056-gbeth", "renesas,rzv2h-gbeth",
				     "snps,dwmac-5.20";
			reg = <0 0x15c30000 0 0x10000>;
			interrupts = <GIC_SPI 765 IRQ_TYPE_LEVEL_HIGH>,
				     <GIC_SPI 767 IRQ_TYPE_LEVEL_HIGH>,
				     <GIC_SPI 766 IRQ_TYPE_LEVEL_HIGH>,
				     <GIC_SPI 772 IRQ_TYPE_LEVEL_HIGH>,
				     <GIC_SPI 773 IRQ_TYPE_LEVEL_HIGH>,
				     <GIC_SPI 774 IRQ_TYPE_LEVEL_HIGH>,
				     <GIC_SPI 775 IRQ_TYPE_LEVEL_HIGH>,
				     <GIC_SPI 768 IRQ_TYPE_LEVEL_HIGH>,
				     <GIC_SPI 769 IRQ_TYPE_LEVEL_HIGH>,
				     <GIC_SPI 770 IRQ_TYPE_LEVEL_HIGH>,
				     <GIC_SPI 771 IRQ_TYPE_LEVEL_HIGH>;
			interrupt-names = "macirq", "eth_wake_irq", "eth_lpi",
					  "rx-queue-0", "rx-queue-1", "rx-queue-2",
					  "rx-queue-3", "tx-queue-0", "tx-queue-1",
					  "tx-queue-2", "tx-queue-3";
			clocks =  <&cpg CPG_MOD 0xbd>, <&cpg CPG_MOD 0xbc>,
				  <&cpg CPG_CORE R9A09G056_GBETH_0_CLK_PTP_REF_I>,
				  <&cpg CPG_MOD 0xb8>, <&cpg CPG_MOD 0xb9>,
				  <&cpg CPG_MOD 0xba>, <&cpg CPG_MOD 0xbb>;
			clock-names = "stmmaceth", "pclk", "ptp_ref",
				      "tx", "rx", "tx-180", "rx-180";
			resets = <&cpg 0xb0>;
			power-domains = <&cpg>;
			renesas,eth-syscon = <&sys 0>;
			snps,multicast-filter-bins = <256>;
			snps,perfect-filter-entries = <128>;
			rx-fifo-depth = <8192>;
			tx-fifo-depth = <8192>;
			snps,fixed-burst;
			snps,no-pbl-x8;
			snps,force_thresh_dma_mode;
			snps,axi-config = <&stmmac_axi_setup>;
			snps,mtl-rx-config = <&mtl_rx_setup0>;
			snps,mtl-tx-config = <&mtl_tx_setup0>;
			snps,txpbl = <32>;
			snps,rxpbl = <32>;
			status = "disabled";

			mdio0: mdio {
				compatible = "snps,dwmac-mdio";
				#address-cells = <1>;
				#size-cells = <0>;
			};

			mtl_rx_setup0: rx-queues-config {
				snps,rx-queues-to-use = <4>;
				snps,rx-sched-sp;

				queue0 {
					snps,dcb-algorithm;
					snps,priority = <0x1>;
					snps,map-to-dma-channel = <0>;
				};

				queue1 {
					snps,dcb-algorithm;
					snps,priority = <0x2>;
					snps,map-to-dma-channel = <1>;
				};

				queue2 {
					snps,dcb-algorithm;
					snps,priority = <0x4>;
					snps,map-to-dma-channel = <2>;
				};

				queue3 {
					snps,dcb-algorithm;
					snps,priority = <0x8>;
					snps,map-to-dma-channel = <3>;
				};
			};

			mtl_tx_setup0: tx-queues-config {
				snps,tx-queues-to-use = <4>;

				queue0 {
					snps,dcb-algorithm;
					snps,priority = <0x1>;
				};

				queue1 {
					snps,dcb-algorithm;
					snps,priority = <0x2>;
				};

				queue2 {
					snps,dcb-algorithm;
					snps,priority = <0x4>;
				};

				queue3 {
					snps,dcb-algorithm;
					snps,priority = <0x8>;
				};
			};
		};

		eth1: ethernet@15c40000 {
			compatible = "renesas,r9a09g056-gbeth", "renesas,rzv2h-gbeth",
				     "snps,dwmac-5.20";
			reg = <0 0x15c40000 0 0x10000>;
			interrupts = <GIC_SPI 780 IRQ_TYPE_LEVEL_HIGH>,
				     <GIC_SPI 782 IRQ_TYPE_LEVEL_HIGH>,
				     <GIC_SPI 781 IRQ_TYPE_LEVEL_HIGH>,
				     <GIC_SPI 787 IRQ_TYPE_LEVEL_HIGH>,
				     <GIC_SPI 788 IRQ_TYPE_LEVEL_HIGH>,
				     <GIC_SPI 789 IRQ_TYPE_LEVEL_HIGH>,
				     <GIC_SPI 790 IRQ_TYPE_LEVEL_HIGH>,
				     <GIC_SPI 783 IRQ_TYPE_LEVEL_HIGH>,
				     <GIC_SPI 784 IRQ_TYPE_LEVEL_HIGH>,
				     <GIC_SPI 785 IRQ_TYPE_LEVEL_HIGH>,
				     <GIC_SPI 786 IRQ_TYPE_LEVEL_HIGH>;
			interrupt-names = "macirq", "eth_wake_irq", "eth_lpi",
					  "rx-queue-0", "rx-queue-1", "rx-queue-2",
					  "rx-queue-3", "tx-queue-0", "tx-queue-1",
					  "tx-queue-2", "tx-queue-3";
			clocks =  <&cpg CPG_MOD 0xc3>, <&cpg CPG_MOD 0xc2>,
				  <&cpg CPG_CORE R9A09G056_GBETH_1_CLK_PTP_REF_I>,
				  <&cpg CPG_MOD 0xbe>, <&cpg CPG_MOD 0xbf>,
				  <&cpg CPG_MOD 0xc0>, <&cpg CPG_MOD 0xc1>;
			clock-names = "stmmaceth", "pclk", "ptp_ref",
				      "tx", "rx", "tx-180", "rx-180";
			resets = <&cpg 0xb1>;
			power-domains = <&cpg>;
			renesas,eth-syscon = <&sys 1>;
			snps,multicast-filter-bins = <256>;
			snps,perfect-filter-entries = <128>;
			rx-fifo-depth = <8192>;
			tx-fifo-depth = <8192>;
			snps,fixed-burst;
			snps,no-pbl-x8;
			snps,force_thresh_dma_mode;
			snps,axi-config = <&stmmac_axi_setup>;
			snps,mtl-rx-config = <&mtl_rx_setup1>;
			snps,mtl-tx-config = <&mtl_tx_setup1>;
			snps,txpbl = <32>;
			snps,rxpbl = <32>;
			status = "disabled";

			mdio1: mdio {
				compatible = "snps,dwmac-mdio";
				#address-cells = <1>;
				#size-cells = <0>;
			};

			mtl_rx_setup1: rx-queues-config {
				snps,rx-queues-to-use = <4>;
				snps,rx-sched-sp;

				queue0 {
					snps,dcb-algorithm;
					snps,priority = <0x1>;
					snps,map-to-dma-channel = <0>;
				};

				queue1 {
					snps,dcb-algorithm;
					snps,priority = <0x2>;
					snps,map-to-dma-channel = <1>;
				};

				queue2 {
					snps,dcb-algorithm;
					snps,priority = <0x4>;
					snps,map-to-dma-channel = <2>;
				};

				queue3 {
					snps,dcb-algorithm;
					snps,priority = <0x8>;
					snps,map-to-dma-channel = <3>;
				};
			};

			mtl_tx_setup1: tx-queues-config {
				snps,tx-queues-to-use = <4>;

				queue0 {
					snps,dcb-algorithm;
					snps,priority = <0x1>;
				};

				queue1 {
					snps,dcb-algorithm;
					snps,priority = <0x2>;
				};

				queue2 {
					snps,dcb-algorithm;
					snps,priority = <0x4>;
				};

				queue3 {
					snps,dcb-algorithm;
					snps,priority = <0x8>;
				};
			};
		};

		cru0: vide0@16000000 {
			compatible = "renesas,r9a09g056-cru", "renesas,rzv2n-cru";
			reg = <0 0x16000000 0 0x400>;
			clocks = <&cpg CPG_MOD 0xd3>,
				 <&cpg CPG_MOD 0xd4>,
				 <&cpg CPG_MOD 0xd2>;
			clock-names = "video", "pclk", "aclk";
			interrupts = <GIC_SPI 838 IRQ_TYPE_LEVEL_HIGH>;
			resets = <&cpg 0xc5>,
				 <&cpg 0xc6>;
			reset-names = "presetn", "aresetn";
			power-domains = <&cpg>;
			channel,id = <0>;
			status = "disabled";

			ports {
				#address-cells = <1>;
				#size-cells = <0>;

				port@1 {
					reg = <1>;
					cru0_to_csi20: endpoint {
						remote-endpoint =
							<&csi20_to_cru0>;
					};
				};
			};
		};

		cru1: video1@16010000 {
			compatible = "renesas,r9a09g056-cru", "renesas,rzv2n-cru";
			reg = <0 0x16010000 0 0x400>;
			clocks = <&cpg CPG_MOD 0xd6>,
				 <&cpg CPG_MOD 0xd7>,
				 <&cpg CPG_MOD 0xd5>;
			clock-names = "video", "pclk", "aclk";
			interrupts = <GIC_SPI 844 IRQ_TYPE_LEVEL_HIGH>;
			resets = <&cpg 0xc8>,
				 <&cpg 0xc9>;
			reset-names = "presetn", "aresetn";
			power-domains = <&cpg>;
			channel,id = <1>;
			status = "disabled";

			ports {
				#address-cells = <1>;
				#size-cells = <0>;

				port@1 {
					reg = <1>;
					cru1_to_csi21: endpoint {
						remote-endpoint =
							<&csi21_to_cru1>;
					};
				};
			};
		};

		csi20: csi20@16000400 {
			compatible = "renesas,r9a09g057-csi2", "renesas,rzv2n-csi2";
			reg = <0 0x16000400 0 0xc00>;
			interrupts = <GIC_SPI 837 IRQ_TYPE_LEVEL_HIGH>;
			clocks = <&cpg CPG_MOD 0xd3>,
				 <&cpg CPG_MOD 0xde>;
			clock-names = "video", "system";
			resets = <&cpg 0xc5>,
				 <&cpg 0xc7>;
			reset-names = "presetn", "cmn-rstb";
			status = "disabled";

			ports {
				#address-cells = <1>;
				#size-cells = <0>;

				port@1 {
					reg = <1>;

					csi20_to_cru0: endpoint {
						remote-endpoint =
							<&cru0_to_csi20>;
					};
				};
			};
		};

		csi21: csi21@16010400 {
			compatible = "renesas,r9a09g057-csi2", "renesas,rzv2n-csi2";
			reg = <0 0x16010400 0 0xc00>;
			interrupts = <GIC_SPI 843 IRQ_TYPE_LEVEL_HIGH>;
			clocks = <&cpg CPG_MOD 0xd6>,
				 <&cpg CPG_MOD 0xdf>;
			clock-names = "video", "system";
			resets = <&cpg 0xc8>,
				 <&cpg 0xca>;
			reset-names = "presetn", "cmn-rstb";
			status = "disabled";

			ports {
				#address-cells = <1>;
				#size-cells = <0>;

				port@1 {
					reg = <1>;

					csi21_to_cru1: endpoint {
						remote-endpoint =
							<&cru1_to_csi21>;
					};
				};
			};
		};

		adc0: adc@11c00000 {
			compatible = "renesas,r9a09g057-adc", "renesas,rzv2h-adc";
			reg = <0 0x11C00000 0 0x400>;
			clocks = <&cpg CPG_MOD 0x108>,
				 <&cpg CPG_MOD 0x107>;
			clock-names = "adclk", "pclk";
			resets =  <&cpg 0xf6>;
			reset-names = "adrst-n";
			power-domains = <&cpg>;
			status = "disabled";
			#address-cells = <1>;
			#size-cells = <0>;
			channel@0 {
				reg = <0>;
			};
			channel@1 {
				reg = <1>;
			};
			channel@2 {
				reg = <2>;
			};
			channel@3 {
				reg = <3>;
			};
			channel@4 {
				reg = <4>;
			};
			channel@5 {
				reg = <5>;
			};
			channel@6 {
				reg = <6>;
			};
			channel@7 {
				reg = <7>;
			};
		};

		adc1: adc@11c02800 {
			compatible = "renesas,r9a09g057-adc", "renesas,rzv2h-adc";
			reg = <0 0x11c02800 0 0x400>;
			clocks = <&cpg CPG_MOD 0x108>,
				 <&cpg CPG_MOD 0x107>;
			clock-names = "adclk", "pclk";
			resets =  <&cpg 0xf6>;
			reset-names = "adrst-n";
			power-domains = <&cpg>;
			status = "disabled";
			#address-cells = <1>;
			#size-cells = <0>;
			channel@0 {
				reg = <0>;
			};
			channel@1 {
				reg = <1>;
			};
			channel@2 {
				reg = <2>;
			};
			channel@3 {
				reg = <3>;
			};
			channel@4 {
				reg = <4>;
			};
			channel@5 {
				reg = <5>;
			};
			channel@6 {
				reg = <6>;
			};
			channel@7 {
				reg = <7>;
			};
		};

		adc2: adc@11c02c00 {
			compatible = "renesas,r9a09g057-adc", "renesas,rzv2h-adc";
			reg = <0 0x11c02c00 0 0x400>;
			clocks = <&cpg CPG_MOD 0x108>,
				 <&cpg CPG_MOD 0x107>;
			clock-names = "adclk", "pclk";
			resets =  <&cpg 0xf6>;
			reset-names = "adrst-n";
			power-domains = <&cpg>;
			status = "disabled";
			#address-cells = <1>;
			#size-cells = <0>;
			channel@0 {
				reg = <0>;
			};
			channel@1 {
				reg = <1>;
			};
			channel@2 {
				reg = <2>;
			};
			channel@3 {
				reg = <3>;
			};
			channel@4 {
				reg = <4>;
			};
			channel@5 {
				reg = <5>;
			};
			channel@6 {
				reg = <6>;
			};
			channel@7 {
				reg = <7>;
			};
		};

		tsu0: thermal@11000000 {
			compatible = "renesas,r9a09g047-tsu";
			reg = <0 0x11000000 0 0x1000>;
			interrupts = <GIC_SPI 248 IRQ_TYPE_EDGE_RISING>,
				     <GIC_SPI 249 IRQ_TYPE_LEVEL_HIGH>;
			interrupt-names = "adi", "adcmpi";
			clocks = <&cpg CPG_MOD 0x109>;
			resets = <&cpg 0xf7>;
			power-domains = <&cpg>;
			#thermal-sensor-cells = <0>;
			renesas,tsu-trim = <&sys 0x320>;
		};

		tsu1: thermal@14002000 {
			compatible = "renesas,r9a09g047-tsu";
			reg = <0 0x14002000 0 0x1000>;
			interrupts = <GIC_SPI 250 IRQ_TYPE_EDGE_RISING>,
				     <GIC_SPI 251 IRQ_TYPE_LEVEL_HIGH>;
			interrupt-names = "adi", "adcmpi";
			clocks = <&cpg CPG_MOD 0x10a>;
			resets = <&cpg 0xf8>;
			power-domains = <&cpg>;
			#thermal-sensor-cells = <0>;
			renesas,tsu-trim = <&sys 0x330>;
		};

		rcar_sound: sound@13c00000 {
			/*
			 * #sound-dai-cells is required
			 *
			 * Single DAI : #sound-dai-cells = <0>; <&rcar_sound>;
			 * Multi  DAI : #sound-dai-cells = <1>; <&rcar_sound N>;
			 */
			/*
			 * #clock-cells is required for audio_clkout0/1/2/3
			 *
			 * clkout       : #clock-cells = <0>;   <&rcar_sound>;
			 * clkout0/1/2/3: #clock-cells = <1>;   <&rcar_sound N>;
			 */
			compatible =  "renesas,rcar_sound-r9a09g056";
			reg =   <0 0x13c00000 0 0x10000>, /* SCU */
				<0 0x13c20000 0 0x10000>, /* ADG */
				<0 0x13c30000 0 0x1000>,  /* SSIU */
				<0 0x13c31000 0 0x1F000>, /* SSI */
				<0 0x13c50000 0 0x10000>, /* Audio DMAC peri peri */
				<0 0x14402400 0 0x3000>;  /* SPDIF */
			reg-names = "scu", "adg", "ssiu", "ssi", "audmapp", "spdif";
			clocks = <&cpg CPG_MOD 0xf5>,
				 <&cpg CPG_MOD 0x18a>,
				 <&cpg CPG_MOD 0x189>,
				 <&cpg CPG_MOD 0x188>,
				 <&cpg CPG_MOD 0x187>,
				 <&cpg CPG_MOD 0x186>,
				 <&cpg CPG_MOD 0x185>,
				 <&cpg CPG_MOD 0x184>,
				 <&cpg CPG_MOD 0x183>,
				 <&cpg CPG_MOD 0x182>,
				 <&cpg CPG_MOD 0x181>,
				 <&cpg CPG_MOD 0x180>,
				 <&cpg CPG_MOD 0xf6>,
				 <&cpg CPG_MOD 0xf7>,
				 <&cpg CPG_MOD 0x17d>,
				 <&cpg CPG_MOD 0x17c>,
				 <&cpg CPG_MOD 0x17b>,
				 <&cpg CPG_MOD 0x17a>,
				 <&cpg CPG_MOD 0x179>,
				 <&cpg CPG_MOD 0x178>,
				 <&cpg CPG_MOD 0x177>,
				 <&cpg CPG_MOD 0x176>,
				 <&cpg CPG_MOD 0x175>,
				 <&cpg CPG_MOD 0x174>,
				 <&cpg CPG_MOD 0x17e>,
				 <&cpg CPG_MOD 0x173>,
				 <&cpg CPG_MOD 0x172>,
				 <&cpg CPG_MOD 0x173>,
				 <&cpg CPG_MOD 0x172>,
				 <&cpg CPG_MOD 0x170>,
				 <&cpg CPG_MOD 0x171>,
				 <&cpg CPG_MOD 0xf8>,
				 <&cpg CPG_MOD 0xf9>,
				 <&cpg CPG_MOD 0xfb>,
				 <&cpg CPG_MOD 0xfc>,
				 <&cpg CPG_MOD 0xfd>,
				 <&cpg CPG_MOD 0xfa>,
				 <&cpg CPG_MOD 0x169>,
				 <&cpg CPG_MOD 0x168>,
				 <&cpg CPG_MOD 0x167>,
				 <&cpg CPG_MOD 0x166>,
				 <&cpg CPG_MOD 0x165>,
				 <&cpg CPG_MOD 0x164>,
				 <&cpg CPG_MOD 0x163>,
				 <&cpg CPG_MOD 0x162>,
				 <&cpg CPG_MOD 0x161>,
				 <&cpg CPG_MOD 0x160>,
				 <&cpg CPG_MOD 0xfe>,
				 <&cpg CPG_MOD 0xff>,
				 <&cpg CPG_MOD 0x100>,
				 <&cpg CPG_MOD 0x16a>,
				 <&cpg CPG_MOD 0x16b>,
				 <&cpg CPG_MOD 0x16c>;
			clock-names = "ssi-all",
				 "ssi.9", "ssi.8", "ssi.7", "ssi.6",
				 "ssi.5", "ssi.4", "ssi.3", "ssi.2",
				 "ssi.1", "ssi.0",
				 "ssif_supply_clk",
				 "scu_clk", "scu_clkx2",
				 "src.9", "src.8", "src.7", "src.6",
				 "src.5", "src.4", "src.3", "src.2",
				 "src.1", "src.0",
				 "scu_supply_clk",
				 "mix.1", "mix.0",
				 "ctu.1", "ctu.0",
				 "dvc.0", "dvc.1",
				 "audmac-pp",
				 "adg_clk",
				 "clk_a", "clk_b", "clk_c", "clk_i",
				 "adg.ssi.9", "adg.ssi.8", "adg.ssi.7", "adg.ssi.6",
				 "adg.ssi.5", "adg.ssi.4", "adg.ssi.3", "adg.ssi.2",
				 "adg.ssi.1", "adg.ssi.0",
				 "spdif.0", "spdif.1", "spdif.2",
				 "adg.spdif.0", "adg.spdif.1", "adg.spdif.2";
			power-domains = <&cpg>;
			resets = <&cpg 0xe1>,
				 <&cpg 0xeb>,
				 <&cpg 0xea>,
				 <&cpg 0xe9>,
				 <&cpg 0xe8>,
				 <&cpg 0xe7>,
				 <&cpg 0xe6>,
				 <&cpg 0xe5>,
				 <&cpg 0xe4>,
				 <&cpg 0xe3>,
				 <&cpg 0xe2>,
				 <&cpg 0xed>,
				 <&cpg 0xec>,
				 <&cpg 0xee>,
				 <&cpg 0xef>,
				 <&cpg 0xf0>,
				 <&cpg 0xf1>;
			reset-names = "ssi-all",
				 "ssi.9", "ssi.8", "ssi.7", "ssi.6",
				 "ssi.5", "ssi.4", "ssi.3", "ssi.2",
				 "ssi.1", "ssi.0",
				 "audmac-pp", "scu",
				 "adg",
				 "spdif.0", "spdif.1", "spdif.2";
			status = "disabled";

			rcar_sound,ctu {
				ctu00: ctu-0 { };
				ctu01: ctu-1 { };
				ctu02: ctu-2 { };
				ctu03: ctu-3 { };
				ctu10: ctu-4 { };
				ctu11: ctu-5 { };
				ctu12: ctu-6 { };
				ctu13: ctu-7 { };
			};

			rcar_sound,dvc {
				dvc0: dvc-0 {
					dmas = <&dmac1 0x1A1DB3>;
					dma-names = "tx";
				};
				dvc1: dvc-1 {
					dmas = <&dmac1 0x1B1DB4>;
					dma-names = "tx";
				};
			};

			rcar_sound,mix {
				mix0: mix-0 { };
				mix1: mix-1 { };
			};

			rcar_sound,src {
				src0: src-0 {
					interrupts = <GIC_SPI 902 IRQ_TYPE_LEVEL_HIGH>;
					dmas = <&dmac1 0x061D9F>, <&dmac2 0x101DA9>;
					dma-names = "rx", "tx";
				};
				src1: src-1 {
					interrupts = <GIC_SPI 903 IRQ_TYPE_LEVEL_HIGH>;
					dmas = <&dmac1 0x071DA0>, <&dmac2 0x111DAA>;
					dma-names = "rx", "tx";
				};
				src2: src-2 {
					interrupts = <GIC_SPI 904 IRQ_TYPE_LEVEL_HIGH>;
					dmas = <&dmac1 0x081DA1>, <&dmac2 0x121DAB>;
					dma-names = "rx", "tx";
				};
				src3: src-3 {
					interrupts = <GIC_SPI 905 IRQ_TYPE_LEVEL_HIGH>;
					dmas = <&dmac1 0x091DA2>, <&dmac2 0x131DAC>;
					dma-names = "rx", "tx";
				};
				src4: src-4 {
					interrupts = <GIC_SPI 906 IRQ_TYPE_LEVEL_HIGH>;
					dmas = <&dmac1 0x0A1DA3>, <&dmac2 0x141DAD>;
					dma-names = "rx", "tx";
				};
				src5: src-5 {
					interrupts = <GIC_SPI 907 IRQ_TYPE_LEVEL_HIGH>;
					dmas = <&dmac1 0x0B1DA4>, <&dmac2 0x151DAE>;
					dma-names = "rx", "tx";
				};
				src6: src-6 {
					interrupts = <GIC_SPI 908 IRQ_TYPE_LEVEL_HIGH>;
					dmas = <&dmac1 0x0C1DA5>, <&dmac2 0x161DAF>;
					dma-names = "rx", "tx";
				};
				src7: src-7 {
					interrupts = <GIC_SPI 909 IRQ_TYPE_LEVEL_HIGH>;
					dmas = <&dmac1 0x0D1DA6>, <&dmac2 0x171DB0>;
					dma-names = "rx", "tx";
				};
				src8: src-8 {
					interrupts = <GIC_SPI 910 IRQ_TYPE_LEVEL_HIGH>;
					dmas = <&dmac1 0x0E1DA7>, <&dmac2 0x181DB1>;
					dma-names = "rx", "tx";
				};
				src9: src-9 {
					interrupts = <GIC_SPI 911 IRQ_TYPE_LEVEL_HIGH>;
					dmas = <&dmac1 0x0F1DA8>, <&dmac2 0x191DB2>;
					dma-names = "rx", "tx";
				};
			};

			rcar_sound,ssi {
				ssi0: ssi-0 {
					interrupts = <GIC_SPI 889 IRQ_TYPE_LEVEL_HIGH>;
				};
				ssi1: ssi-1 {
					interrupts = <GIC_SPI 890 IRQ_TYPE_LEVEL_HIGH>;
				};
				ssi2: ssi-2 {
					interrupts = <GIC_SPI 891 IRQ_TYPE_LEVEL_HIGH>;
				};
				ssi3: ssi-3 {
					interrupts = <GIC_SPI 892 IRQ_TYPE_LEVEL_HIGH>;
				};
				ssi4: ssi-4 {
					interrupts = <GIC_SPI 893 IRQ_TYPE_LEVEL_HIGH>;
				};
				ssi5: ssi-5 {
					interrupts = <GIC_SPI 894 IRQ_TYPE_LEVEL_HIGH>;
				};
				ssi6: ssi-6 {
					interrupts = <GIC_SPI 895 IRQ_TYPE_LEVEL_HIGH>;
				};
				ssi7: ssi-7 {
					interrupts = <GIC_SPI 896 IRQ_TYPE_LEVEL_HIGH>;
				};
				ssi8: ssi-8 {
					interrupts = <GIC_SPI 897 IRQ_TYPE_LEVEL_HIGH>;
				};
				ssi9: ssi-9 {
					interrupts = <GIC_SPI 898 IRQ_TYPE_LEVEL_HIGH>;
				};
			};

			rcar_sound,ssiu {
				ssiu00: ssiu-0 {
					dmas = <&dmac1 0x1C1D61>, <&dmac2 0x1D1D62>;
					dma-names = "tx", "rx";
				};
				ssiu01: ssiu-1 {
					dmas = <&dmac1 0x1E1D63>, <&dmac2 0x1F1D64>;
					dma-names = "tx", "rx";
				};
				ssiu02: ssiu-2 {
					dmas = <&dmac1 0x201D65>, <&dmac2 0x211D66>;
					dma-names = "tx", "rx";
				};
				ssiu03: ssiu-3 {
					dmas = <&dmac1 0x221D67>, <&dmac2 0x231D68>;
					dma-names = "tx", "rx";
				};
				ssiu10: ssiu-4 {
					dmas = <&dmac1 0x241D69>, <&dmac2 0x251D6A>;
					dma-names = "tx", "rx";
				};
				ssiu11: ssiu-5 {
					dmas = <&dmac1 0x261D6B>, <&dmac2 0x271D6C>;
					dma-names = "tx", "rx";
				};
				ssiu12: ssiu-6 {
					dmas = <&dmac1 0x281D6D>, <&dmac2 0x291D6E>;
					dma-names = "tx", "rx";
				};
				ssiu13: ssiu-7 {
					dmas = <&dmac1 0x2A1D6F>, <&dmac2 0x2B1D70>;
					dma-names = "tx", "rx";
				};
				ssiu20: ssiu-8 {
					dmas = <&dmac1 0x2C1D71>, <&dmac2 0x2D1D72>;
					dma-names = "tx", "rx";
				};
				ssiu21: ssiu-9 {
					dmas = <&dmac1 0x2E1D73>, <&dmac2 0x2F1D74>;
					dma-names = "tx", "rx";
				};
				ssiu22: ssiu-10 {
					dmas = <&dmac1 0x301D75>, <&dmac2 0x311D76>;
					dma-names = "tx", "rx";
				};
				ssiu23: ssiu-11 {
					dmas = <&dmac1 0x321D77>, <&dmac2 0x331D78>;
					dma-names = "tx", "rx";
				};
				ssiu30: ssiu-12 {
					dmas = <&dmac1 0x341D79>, <&dmac2 0x351D7A>;
					dma-names = "tx", "rx";
				};
				ssiu31: ssiu-13 {
					dmas = <&dmac1 0x361D7B>, <&dmac2 0x371D7C>;
					dma-names = "tx", "rx";
				};
				ssiu32: ssiu-14 {
					dmas = <&dmac1 0x381D7D>, <&dmac2 0x391D7E>;
					dma-names = "tx", "rx";
				};
				ssiu33: ssiu-15 {
					dmas = <&dmac1 0x3A1D7F>, <&dmac2 0x3B1D80>;
					dma-names = "tx", "rx";
				};
				ssiu40: ssiu-16 {
					dmas = <&dmac1 0x3C1D81>, <&dmac2 0x3D1D82>;
					dma-names = "tx", "rx";
				};
				ssiu41: ssiu-17 {
					dmas = <&dmac1 0x3E1D83>, <&dmac2 0x3F1D84>;
					dma-names = "tx", "rx";
				};
				ssiu42: ssiu-18 {
					dmas = <&dmac1 0x401D85>, <&dmac2 0x411D86>;
					dma-names = "tx", "rx";
				};
				ssiu43: ssiu-19 {
					dmas = <&dmac1 0x421D87>, <&dmac2 0x431D88>;
					dma-names = "tx", "rx";
				};
				ssiu50: ssiu-20 {
					dmas = <&dmac1 0x441D89>, <&dmac2 0x451D8A>;
					dma-names = "tx", "rx";
				};
				ssiu60: ssiu-21 {
					dmas = <&dmac1 0x461D8B>, <&dmac2 0x471D8C>;
					dma-names = "tx","rx";
				};
				ssiu70: ssiu-22 {
					dmas = <&dmac1 0x481D8D>, <&dmac2 0x491D8E>;
					dma-names = "tx", "rx";
				};
				ssiu80: ssiu-23 {
					dmas = <&dmac1 0x4A1D8F>, <&dmac2 0x4B1D90>;
					dma-names = "tx", "rx";
				};
				ssiu90: ssiu-24 {
					dmas = <&dmac1 0x4C1D91>, <&dmac2 0x4D1D92>;
					dma-names = "tx", "rx";
				};
				ssiu91: ssiu-25 {
					dmas = <&dmac1 0x4E1D93>, <&dmac2 0x4F1D94>;
					dma-names = "tx", "rx";
				};
				ssiu92: ssiu-26 {
					dmas = <&dmac1 0x501D95>, <&dmac2 0x511D96>;
					dma-names = "tx", "rx";
				};
				ssiu93: ssiu-27 {
					dmas = <&dmac1 0x521D97>, <&dmac2 0x531D98>;
					dma-names = "tx", "rx";
				};
			};

			rcar_sound,spdif {
				spdif0: spdif-0 {
					interrupts = <GIC_SPI 899 IRQ_TYPE_LEVEL_HIGH>;
					dmas = <&dmac1 0x011D9A>, <&dmac2 0x001D99>;
					dma-names = "tx", "rx";
				};
				spdif1: spdif-1 {
					interrupts = <GIC_SPI 900 IRQ_TYPE_LEVEL_HIGH>;
					dmas = <&dmac1 0x031D9C>, <&dmac2 0x021D9B>;
					dma-names = "tx", "rx";
				};
				spdif2: spdif-2 {
					interrupts = <GIC_SPI 901 IRQ_TYPE_LEVEL_HIGH>;
					dmas = <&dmac1 0x051D9E>, <&dmac2 0x041D9D>;
					dma-names = "tx", "rx";
				};
			};
		};
	};

	thermal-zones {
		emergency {
			polling-delay = <1000>;
			on-temperature = <110000>;
			off-temperature = <95000>;
			target_cpus = <&cpu1 &cpu2 &cpu3>;
			status = "disabled";
		};
		cpu-thermal0 {
			polling-delay = <1000>;
			polling-delay-passive = <250>;
			thermal-sensors = <&tsu0>;

			cooling-maps {
				map0 {
					trip = <&target0>;
					cooling-device = <&cpu0 0 3>, <&cpu1 0 3>,
							 <&cpu2 0 3>, <&cpu3 0 3>;
					contribution = <1024>;
				};
			};

			trips {
				target0: trip-point {
					temperature = <95000>;
					hysteresis = <1000>;
					type = "passive";
				};

				sensor0_crit: sensor-crit {
					temperature = <120000>;
					hysteresis = <1000>;
					type = "critical";
				};
			};
		};

		cpu-thermal1 {
			polling-delay = <1000>;
			polling-delay-passive = <250>;
			thermal-sensors = <&tsu1>;

			cooling-maps {
				map0 {
					trip = <&target1>;
					cooling-device = <&cpu0 0 3>, <&cpu1 0 3>,
							 <&cpu2 0 3>, <&cpu3 0 3>;
					contribution = <1024>;
				};
			};

			trips {
				target1: trip-point {
					temperature = <95000>;
					hysteresis = <1000>;
					type = "passive";
				};

				sensor1_crit: sensor-crit {
					temperature = <120000>;
					hysteresis = <1000>;
					type = "critical";
				};
			};
		};
	};

	stmmac_axi_setup: stmmac-axi-config {
		snps,lpi_en;
		snps,wr_osr_lmt = <0xf>;
		snps,rd_osr_lmt = <0xf>;
		snps,blen = <16 8 4 0 0 0 0>;
	};

	timer {
		compatible = "arm,armv8-timer";
		interrupts-extended = <&gic GIC_PPI 13 IRQ_TYPE_LEVEL_LOW>,
				      <&gic GIC_PPI 14 IRQ_TYPE_LEVEL_LOW>,
				      <&gic GIC_PPI 11 IRQ_TYPE_LEVEL_LOW>,
				      <&gic GIC_PPI 10 IRQ_TYPE_LEVEL_LOW>,
				      <&gic GIC_PPI 12 IRQ_TYPE_LEVEL_LOW>;
		interrupt-names = "sec-phys", "phys", "virt", "hyp-phys", "hyp-virt";
	};
};
